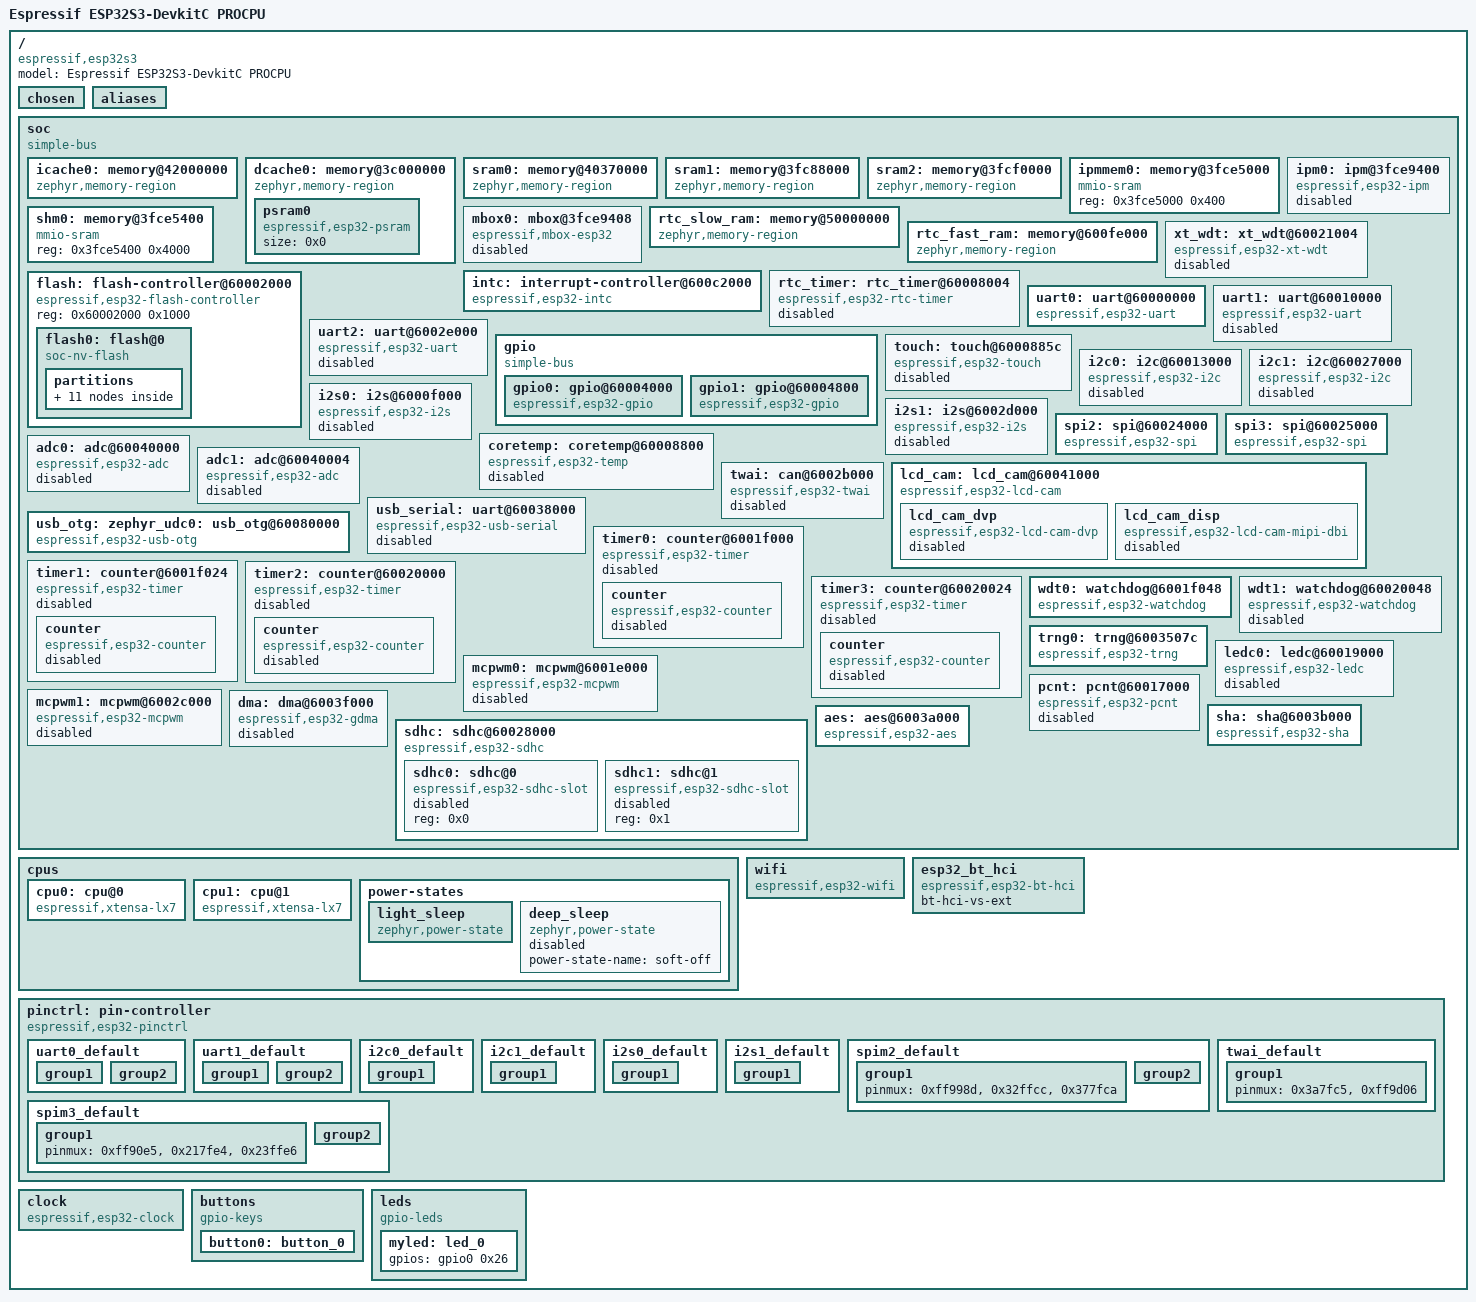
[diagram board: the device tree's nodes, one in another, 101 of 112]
/dts-v1/;

/* node '/' defined in zephyr\dts\common\skeleton.dtsi:9 */
/ {
	#address-cells = < 0x1 >;                   /* in zephyr\dts\common\skeleton.dtsi:10 */
	#size-cells = < 0x1 >;                      /* in zephyr\dts\common\skeleton.dtsi:11 */
	model = "Espressif ESP32S3-DevkitC PROCPU"; /* in zephyr\boards\espressif\esp32s3_devkitc\esp32s3_devkitc_procpu.dts:15 */
	compatible = "espressif,esp32s3";           /* in zephyr\boards\espressif\esp32s3_devkitc\esp32s3_devkitc_procpu.dts:16 */

	/* node '/chosen' defined in zephyr\dts\common\skeleton.dtsi:13 */
	chosen {
		zephyr,canbus = &twai;                    /* in zephyr\dts\xtensa\espressif\esp32s3\esp32s3_common.dtsi:22 */
		zephyr,entropy = &trng0;                  /* in zephyr\dts\xtensa\espressif\esp32s3\esp32s3_common.dtsi:23 */
		zephyr,flash-controller = &flash;         /* in zephyr\dts\xtensa\espressif\esp32s3\esp32s3_common.dtsi:24 */
		zephyr,sram = &sram1;                     /* in zephyr\boards\espressif\esp32s3_devkitc\esp32s3_devkitc_procpu.dts:26 */
		zephyr,console = &uart0;                  /* in zephyr\boards\espressif\esp32s3_devkitc\esp32s3_devkitc_procpu.dts:27 */
		zephyr,shell-uart = &uart0;               /* in zephyr\boards\espressif\esp32s3_devkitc\esp32s3_devkitc_procpu.dts:28 */
		zephyr,flash = &flash0;                   /* in zephyr\boards\espressif\esp32s3_devkitc\esp32s3_devkitc_procpu.dts:29 */
		zephyr,code-partition = &slot0_partition; /* in zephyr\boards\espressif\esp32s3_devkitc\esp32s3_devkitc_procpu.dts:30 */
		zephyr,bt-hci = &esp32_bt_hci;            /* in zephyr\boards\espressif\esp32s3_devkitc\esp32s3_devkitc_procpu.dts:31 */
	};

	/* node '/aliases' defined in zephyr\dts\common\skeleton.dtsi:15 */
	aliases {
		die-temp0 = &coretemp; /* in zephyr\dts\xtensa\espressif\esp32s3\esp32s3_common.dtsi:18 */
		i2c-0 = &i2c0;         /* in zephyr\boards\espressif\esp32s3_devkitc\esp32s3_devkitc_procpu.dts:19 */
		watchdog0 = &wdt0;     /* in zephyr\boards\espressif\esp32s3_devkitc\esp32s3_devkitc_procpu.dts:20 */
		uart-0 = &uart0;       /* in zephyr\boards\espressif\esp32s3_devkitc\esp32s3_devkitc_procpu.dts:21 */
		sw0 = &button0;        /* in zephyr\boards\espressif\esp32s3_devkitc\esp32s3_devkitc_procpu.dts:22 */
		led0 = &myled;         /* in ..\ZephyrWrokSpace\lomico\zephyr-course\my_work_space\hello_led\boards\esp32s3_devkitc_procpu.overlay:3 */
	};

	/* node '/soc' defined in zephyr\dts\xtensa\xtensa.dtsi:10 */
	soc {
		#address-cells = < 0x1 >;  /* in zephyr\dts\xtensa\espressif\esp32s3\esp32s3_common.dtsi:97 */
		#size-cells = < 0x1 >;     /* in zephyr\dts\xtensa\espressif\esp32s3\esp32s3_common.dtsi:98 */
		compatible = "simple-bus"; /* in zephyr\dts\xtensa\espressif\esp32s3\esp32s3_common.dtsi:99 */
		ranges;                    /* in zephyr\dts\xtensa\espressif\esp32s3\esp32s3_common.dtsi:100 */

		/* node '/soc/memory@42000000' defined in zephyr\dts\xtensa\espressif\esp32s3\esp32s3_common.dtsi:102 */
		icache0: memory@42000000 {
			compatible = "zephyr,memory-region"; /* in zephyr\dts\xtensa\espressif\esp32s3\esp32s3_common.dtsi:103 */
			reg = < 0x42000000 0x2000000 >;      /* in zephyr\dts\xtensa\espressif\esp32s3\esp32s3_common.dtsi:104 */
			zephyr,memory-region = "ICACHE0";    /* in zephyr\dts\xtensa\espressif\esp32s3\esp32s3_common.dtsi:105 */
		};

		/* node '/soc/memory@3c000000' defined in zephyr\dts\xtensa\espressif\esp32s3\esp32s3_common.dtsi:108 */
		dcache0: memory@3c000000 {
			compatible = "zephyr,memory-region"; /* in zephyr\dts\xtensa\espressif\esp32s3\esp32s3_common.dtsi:109 */
			reg = < 0x3c000000 0x2000000 >;      /* in zephyr\dts\xtensa\espressif\esp32s3\esp32s3_common.dtsi:110 */
			zephyr,memory-region = "DCACHE0";    /* in zephyr\dts\xtensa\espressif\esp32s3\esp32s3_common.dtsi:111 */

			/* node '/soc/memory@3c000000/psram0' defined in zephyr\dts\xtensa\espressif\esp32s3\esp32s3_common.dtsi:113 */
			psram0: psram0 {
				compatible = "espressif,esp32-psram"; /* in zephyr\dts\xtensa\espressif\esp32s3\esp32s3_common.dtsi:114 */
				size = < 0x0 >;                       /* in zephyr\dts\xtensa\espressif\esp32s3\esp32s3_common.dtsi:115 */
			};
		};

		/* node '/soc/memory@40370000' defined in zephyr\dts\xtensa\espressif\esp32s3\esp32s3_common.dtsi:119 */
		sram0: memory@40370000 {
			compatible = "zephyr,memory-region",
			             "mmio-sram";            /* in zephyr\dts\xtensa\espressif\esp32s3\esp32s3_common.dtsi:120 */
			reg = < 0x40370000 0x8000 >;         /* in zephyr\dts\xtensa\espressif\esp32s3\esp32s3_common.dtsi:121 */
			zephyr,memory-region = "SRAM0";      /* in zephyr\dts\xtensa\espressif\esp32s3\esp32s3_common.dtsi:122 */
		};

		/* node '/soc/memory@3fc88000' defined in zephyr\dts\xtensa\espressif\esp32s3\esp32s3_common.dtsi:125 */
		sram1: memory@3fc88000 {
			compatible = "zephyr,memory-region",
			             "mmio-sram";            /* in zephyr\dts\xtensa\espressif\esp32s3\esp32s3_common.dtsi:126 */
			reg = < 0x3fc88000 0x68000 >;        /* in zephyr\dts\xtensa\espressif\esp32s3\esp32s3_common.dtsi:127 */
			zephyr,memory-region = "SRAM1";      /* in zephyr\dts\xtensa\espressif\esp32s3\esp32s3_common.dtsi:128 */
		};

		/* node '/soc/memory@3fcf0000' defined in zephyr\dts\xtensa\espressif\esp32s3\esp32s3_common.dtsi:131 */
		sram2: memory@3fcf0000 {
			compatible = "zephyr,memory-region",
			             "mmio-sram";            /* in zephyr\dts\xtensa\espressif\esp32s3\esp32s3_common.dtsi:132 */
			reg = < 0x3fcf0000 0x10000 >;        /* in zephyr\dts\xtensa\espressif\esp32s3\esp32s3_common.dtsi:133 */
			zephyr,memory-region = "SRAM2";      /* in zephyr\dts\xtensa\espressif\esp32s3\esp32s3_common.dtsi:134 */
		};

		/* node '/soc/memory@3fce5000' defined in zephyr\dts\xtensa\espressif\esp32s3\esp32s3_common.dtsi:137 */
		ipmmem0: memory@3fce5000 {
			compatible = "mmio-sram";   /* in zephyr\dts\xtensa\espressif\esp32s3\esp32s3_common.dtsi:138 */
			reg = < 0x3fce5000 0x400 >; /* in zephyr\dts\xtensa\espressif\esp32s3\esp32s3_common.dtsi:139 */
			phandle = < 0x1 >;          /* in zephyr\dts\xtensa\espressif\esp32s3\esp32s3_common.dtsi:151 */
		};

		/* node '/soc/memory@3fce5400' defined in zephyr\dts\xtensa\espressif\esp32s3\esp32s3_common.dtsi:142 */
		shm0: memory@3fce5400 {
			compatible = "mmio-sram";    /* in zephyr\dts\xtensa\espressif\esp32s3\esp32s3_common.dtsi:143 */
			reg = < 0x3fce5400 0x4000 >; /* in zephyr\dts\xtensa\espressif\esp32s3\esp32s3_common.dtsi:144 */
		};

		/* node '/soc/ipm@3fce9400' defined in zephyr\dts\xtensa\espressif\esp32s3\esp32s3_common.dtsi:147 */
		ipm0: ipm@3fce9400 {
			compatible = "espressif,esp32-ipm"; /* in zephyr\dts\xtensa\espressif\esp32s3\esp32s3_common.dtsi:148 */
			reg = < 0x3fce9400 0x8 >;           /* in zephyr\dts\xtensa\espressif\esp32s3\esp32s3_common.dtsi:149 */
			status = "disabled";                /* in zephyr\dts\xtensa\espressif\esp32s3\esp32s3_common.dtsi:150 */
			shared-memory = < &ipmmem0 >;       /* in zephyr\dts\xtensa\espressif\esp32s3\esp32s3_common.dtsi:151 */
			shared-memory-size = < 0x400 >;     /* in zephyr\dts\xtensa\espressif\esp32s3\esp32s3_common.dtsi:152 */
			interrupts = < 0x4f 0x0 0x0 >,
			             < 0x50 0x0 0x0 >;      /* in zephyr\dts\xtensa\espressif\esp32s3\esp32s3_common.dtsi:153 */
			interrupt-parent = < &intc >;       /* in zephyr\dts\xtensa\espressif\esp32s3\esp32s3_common.dtsi:155 */
		};

		/* node '/soc/mbox@3fce9408' defined in zephyr\dts\xtensa\espressif\esp32s3\esp32s3_common.dtsi:158 */
		mbox0: mbox@3fce9408 {
			compatible = "espressif,mbox-esp32"; /* in zephyr\dts\xtensa\espressif\esp32s3\esp32s3_common.dtsi:159 */
			reg = < 0x3fce9408 0x8 >;            /* in zephyr\dts\xtensa\espressif\esp32s3\esp32s3_common.dtsi:160 */
			status = "disabled";                 /* in zephyr\dts\xtensa\espressif\esp32s3\esp32s3_common.dtsi:161 */
			shared-memory = < &ipmmem0 >;        /* in zephyr\dts\xtensa\espressif\esp32s3\esp32s3_common.dtsi:162 */
			shared-memory-size = < 0x400 >;      /* in zephyr\dts\xtensa\espressif\esp32s3\esp32s3_common.dtsi:163 */
			interrupts = < 0x4f 0x0 0x0 >,
			             < 0x50 0x0 0x0 >;       /* in zephyr\dts\xtensa\espressif\esp32s3\esp32s3_common.dtsi:164 */
			interrupt-parent = < &intc >;        /* in zephyr\dts\xtensa\espressif\esp32s3\esp32s3_common.dtsi:166 */
			#mbox-cells = < 0x1 >;               /* in zephyr\dts\xtensa\espressif\esp32s3\esp32s3_common.dtsi:167 */
		};

		/* node '/soc/memory@50000000' defined in zephyr\dts\xtensa\espressif\esp32s3\esp32s3_common.dtsi:170 */
		rtc_slow_ram: memory@50000000 {
			compatible = "zephyr,memory-region",
			             "mmio-sram";              /* in zephyr\dts\xtensa\espressif\esp32s3\esp32s3_common.dtsi:171 */
			reg = < 0x50000000 0x2000 >;           /* in zephyr\dts\xtensa\espressif\esp32s3\esp32s3_common.dtsi:172 */
			zephyr,memory-region = "RTC_SLOW_RAM"; /* in zephyr\dts\xtensa\espressif\esp32s3\esp32s3_common.dtsi:173 */
		};

		/* node '/soc/memory@600fe000' defined in zephyr\dts\xtensa\espressif\esp32s3\esp32s3_common.dtsi:176 */
		rtc_fast_ram: memory@600fe000 {
			compatible = "zephyr,memory-region",
			             "mmio-sram";              /* in zephyr\dts\xtensa\espressif\esp32s3\esp32s3_common.dtsi:177 */
			reg = < 0x600fe000 0x2000 >;           /* in zephyr\dts\xtensa\espressif\esp32s3\esp32s3_common.dtsi:178 */
			zephyr,memory-region = "RTC_FAST_RAM"; /* in zephyr\dts\xtensa\espressif\esp32s3\esp32s3_common.dtsi:179 */
		};

		/* node '/soc/interrupt-controller@600c2000' defined in zephyr\dts\xtensa\espressif\esp32s3\esp32s3_common.dtsi:182 */
		intc: interrupt-controller@600c2000 {
			#interrupt-cells = < 0x3 >;          /* in zephyr\dts\xtensa\espressif\esp32s3\esp32s3_common.dtsi:183 */
			#address-cells = < 0x0 >;            /* in zephyr\dts\xtensa\espressif\esp32s3\esp32s3_common.dtsi:184 */
			compatible = "espressif,esp32-intc"; /* in zephyr\dts\xtensa\espressif\esp32s3\esp32s3_common.dtsi:185 */
			interrupt-controller;                /* in zephyr\dts\xtensa\espressif\esp32s3\esp32s3_common.dtsi:186 */
			reg = < 0x600c2000 0x1000 >;         /* in zephyr\dts\xtensa\espressif\esp32s3\esp32s3_common.dtsi:187 */
			status = "okay";                     /* in zephyr\dts\xtensa\espressif\esp32s3\esp32s3_common.dtsi:188 */
			phandle = < 0x2 >;                   /* in zephyr\dts\xtensa\espressif\esp32s3\esp32s3_common.dtsi:155 */
		};

		/* node '/soc/xt_wdt@60021004' defined in zephyr\dts\xtensa\espressif\esp32s3\esp32s3_common.dtsi:191 */
		xt_wdt: xt_wdt@60021004 {
			compatible = "espressif,esp32-xt-wdt"; /* in zephyr\dts\xtensa\espressif\esp32s3\esp32s3_common.dtsi:192 */
			reg = < 0x60021004 0x4 >;              /* in zephyr\dts\xtensa\espressif\esp32s3\esp32s3_common.dtsi:193 */
			clocks = < &clock 0xc >;               /* in zephyr\dts\xtensa\espressif\esp32s3\esp32s3_common.dtsi:194 */
			interrupts = < 0x27 0x0 0x0 >;         /* in zephyr\dts\xtensa\espressif\esp32s3\esp32s3_common.dtsi:195 */
			interrupt-parent = < &intc >;          /* in zephyr\dts\xtensa\espressif\esp32s3\esp32s3_common.dtsi:196 */
			status = "disabled";                   /* in zephyr\dts\xtensa\espressif\esp32s3\esp32s3_common.dtsi:197 */
		};

		/* node '/soc/rtc_timer@60008004' defined in zephyr\dts\xtensa\espressif\esp32s3\esp32s3_common.dtsi:200 */
		rtc_timer: rtc_timer@60008004 {
			reg = < 0x60008004 0xc >;                 /* in zephyr\dts\xtensa\espressif\esp32s3\esp32s3_common.dtsi:201 */
			compatible = "espressif,esp32-rtc-timer"; /* in zephyr\dts\xtensa\espressif\esp32s3\esp32s3_common.dtsi:202 */
			clocks = < &clock 0xc >;                  /* in zephyr\dts\xtensa\espressif\esp32s3\esp32s3_common.dtsi:203 */
			interrupts = < 0x27 0x0 0x0 >;            /* in zephyr\dts\xtensa\espressif\esp32s3\esp32s3_common.dtsi:204 */
			interrupt-parent = < &intc >;             /* in zephyr\dts\xtensa\espressif\esp32s3\esp32s3_common.dtsi:205 */
			status = "disabled";                      /* in zephyr\dts\xtensa\espressif\esp32s3\esp32s3_common.dtsi:206 */
		};

		/* node '/soc/flash-controller@60002000' defined in zephyr\dts\xtensa\espressif\esp32s3\esp32s3_common.dtsi:209 */
		flash: flash-controller@60002000 {
			compatible = "espressif,esp32-flash-controller"; /* in zephyr\dts\xtensa\espressif\esp32s3\esp32s3_common.dtsi:210 */
			reg = < 0x60002000 0x1000 >;                     /* in zephyr\dts\xtensa\espressif\esp32s3\esp32s3_common.dtsi:211 */
			#address-cells = < 0x1 >;                        /* in zephyr\dts\xtensa\espressif\esp32s3\esp32s3_common.dtsi:212 */
			#size-cells = < 0x1 >;                           /* in zephyr\dts\xtensa\espressif\esp32s3\esp32s3_common.dtsi:213 */
			ranges;                                          /* in zephyr\dts\xtensa\espressif\esp32s3\esp32s3_common.dtsi:214 */

			/* node '/soc/flash-controller@60002000/flash@0' defined in zephyr\dts\xtensa\espressif\esp32s3\esp32s3_common.dtsi:216 */
			flash0: flash@0 {
				compatible = "soc-nv-flash";   /* in zephyr\dts\xtensa\espressif\esp32s3\esp32s3_common.dtsi:217 */
				erase-block-size = < 0x1000 >; /* in zephyr\dts\xtensa\espressif\esp32s3\esp32s3_common.dtsi:218 */
				write-block-size = < 0x4 >;    /* in zephyr\dts\xtensa\espressif\esp32s3\esp32s3_common.dtsi:219 */
				#address-cells = < 0x1 >;      /* in zephyr\dts\xtensa\espressif\esp32s3\esp32s3_common.dtsi:220 */
				#size-cells = < 0x1 >;         /* in zephyr\dts\xtensa\espressif\esp32s3\esp32s3_common.dtsi:221 */
				reg = < 0x0 0x800000 >;        /* in zephyr\dts\xtensa\espressif\esp32s3\esp32s3_wroom_n8.dtsi:11 */
				ranges = < 0x0 0x0 0x800000 >; /* in zephyr\dts\xtensa\espressif\esp32s3\esp32s3_wroom_n8.dtsi:12 */

				/* node '/soc/flash-controller@60002000/flash@0/partitions' defined in zephyr\dts\vendor\espressif\partitions_0x0_amp_4M.dtsi:8 */
				partitions {
					ranges;                   /* in zephyr\dts\vendor\espressif\partitions_0x0_amp_4M.dtsi:9 */
					#address-cells = < 0x1 >; /* in zephyr\dts\vendor\espressif\partitions_0x0_amp_4M.dtsi:10 */
					#size-cells = < 0x1 >;    /* in zephyr\dts\vendor\espressif\partitions_0x0_amp_4M.dtsi:11 */

					/* node '/soc/flash-controller@60002000/flash@0/partitions/partition@0' defined in zephyr\dts\vendor\espressif\partitions_0x0_amp_4M.dtsi:13 */
					boot_partition: partition@0 {
						compatible = "zephyr,mapped-partition"; /* in zephyr\dts\vendor\espressif\partitions_0x0_amp_4M.dtsi:14 */
						label = "mcuboot";                      /* in zephyr\dts\vendor\espressif\partitions_0x0_amp_4M.dtsi:15 */
						reg = < 0x0 0x10000 >;                  /* in zephyr\dts\vendor\espressif\partitions_0x0_amp_4M.dtsi:16 */
					};

					/* node '/soc/flash-controller@60002000/flash@0/partitions/partition@10000' defined in zephyr\dts\vendor\espressif\partitions_0x0_amp_4M.dtsi:19 */
					sys_partition: partition@10000 {
						compatible = "zephyr,mapped-partition"; /* in zephyr\dts\vendor\espressif\partitions_0x0_amp_4M.dtsi:20 */
						label = "sys";                          /* in zephyr\dts\vendor\espressif\partitions_0x0_amp_4M.dtsi:21 */
						reg = < 0x10000 0x10000 >;              /* in zephyr\dts\vendor\espressif\partitions_0x0_amp_4M.dtsi:22 */
					};

					/* node '/soc/flash-controller@60002000/flash@0/partitions/partition@20000' defined in zephyr\dts\vendor\espressif\partitions_0x0_amp_4M.dtsi:25 */
					slot0_partition: partition@20000 {
						compatible = "zephyr,mapped-partition"; /* in zephyr\dts\vendor\espressif\partitions_0x0_amp_4M.dtsi:26 */
						label = "image-0";                      /* in zephyr\dts\vendor\espressif\partitions_0x0_amp_4M.dtsi:27 */
						reg = < 0x20000 0x150000 >;             /* in zephyr\dts\vendor\espressif\partitions_0x0_amp_4M.dtsi:28 */
					};

					/* node '/soc/flash-controller@60002000/flash@0/partitions/partition@170000' defined in zephyr\dts\vendor\espressif\partitions_0x0_amp_4M.dtsi:31 */
					slot1_partition: partition@170000 {
						compatible = "zephyr,mapped-partition"; /* in zephyr\dts\vendor\espressif\partitions_0x0_amp_4M.dtsi:32 */
						label = "image-1";                      /* in zephyr\dts\vendor\espressif\partitions_0x0_amp_4M.dtsi:33 */
						reg = < 0x170000 0x150000 >;            /* in zephyr\dts\vendor\espressif\partitions_0x0_amp_4M.dtsi:34 */
					};

					/* node '/soc/flash-controller@60002000/flash@0/partitions/partition@2c0000' defined in zephyr\dts\vendor\espressif\partitions_0x0_amp_4M.dtsi:37 */
					slot0_appcpu_partition: partition@2c0000 {
						compatible = "zephyr,mapped-partition"; /* in zephyr\dts\vendor\espressif\partitions_0x0_amp_4M.dtsi:38 */
						label = "image-0-appcpu";               /* in zephyr\dts\vendor\espressif\partitions_0x0_amp_4M.dtsi:39 */
						reg = < 0x2c0000 0x70000 >;             /* in zephyr\dts\vendor\espressif\partitions_0x0_amp_4M.dtsi:40 */
					};

					/* node '/soc/flash-controller@60002000/flash@0/partitions/partition@330000' defined in zephyr\dts\vendor\espressif\partitions_0x0_amp_4M.dtsi:43 */
					slot1_appcpu_partition: partition@330000 {
						compatible = "zephyr,mapped-partition"; /* in zephyr\dts\vendor\espressif\partitions_0x0_amp_4M.dtsi:44 */
						label = "image-1-appcpu";               /* in zephyr\dts\vendor\espressif\partitions_0x0_amp_4M.dtsi:45 */
						reg = < 0x330000 0x70000 >;             /* in zephyr\dts\vendor\espressif\partitions_0x0_amp_4M.dtsi:46 */
					};

					/* node '/soc/flash-controller@60002000/flash@0/partitions/partition@3a0000' defined in zephyr\dts\vendor\espressif\partitions_0x0_amp_4M.dtsi:49 */
					slot0_lpcore_partition: partition@3a0000 {
						compatible = "zephyr,mapped-partition"; /* in zephyr\dts\vendor\espressif\partitions_0x0_amp_4M.dtsi:50 */
						label = "image-0-lpcore";               /* in zephyr\dts\vendor\espressif\partitions_0x0_amp_4M.dtsi:51 */
						reg = < 0x3a0000 0x8000 >;              /* in zephyr\dts\vendor\espressif\partitions_0x0_amp_4M.dtsi:52 */
					};

					/* node '/soc/flash-controller@60002000/flash@0/partitions/partition@3a8000' defined in zephyr\dts\vendor\espressif\partitions_0x0_amp_4M.dtsi:55 */
					slot1_lpcore_partition: partition@3a8000 {
						compatible = "zephyr,mapped-partition"; /* in zephyr\dts\vendor\espressif\partitions_0x0_amp_4M.dtsi:56 */
						label = "image-1-lpcore";               /* in zephyr\dts\vendor\espressif\partitions_0x0_amp_4M.dtsi:57 */
						reg = < 0x3a8000 0x8000 >;              /* in zephyr\dts\vendor\espressif\partitions_0x0_amp_4M.dtsi:58 */
					};

					/* node '/soc/flash-controller@60002000/flash@0/partitions/partition@3b0000' defined in zephyr\dts\vendor\espressif\partitions_0x0_amp_4M.dtsi:61 */
					storage_partition: partition@3b0000 {
						compatible = "zephyr,mapped-partition"; /* in zephyr\dts\vendor\espressif\partitions_0x0_amp_4M.dtsi:62 */
						label = "storage";                      /* in zephyr\dts\vendor\espressif\partitions_0x0_amp_4M.dtsi:63 */
						reg = < 0x3b0000 0x30000 >;             /* in zephyr\dts\vendor\espressif\partitions_0x0_amp_4M.dtsi:64 */
					};

					/* node '/soc/flash-controller@60002000/flash@0/partitions/partition@3e0000' defined in zephyr\dts\vendor\espressif\partitions_0x0_amp_4M.dtsi:67 */
					scratch_partition: partition@3e0000 {
						compatible = "zephyr,mapped-partition"; /* in zephyr\dts\vendor\espressif\partitions_0x0_amp_4M.dtsi:68 */
						label = "image-scratch";                /* in zephyr\dts\vendor\espressif\partitions_0x0_amp_4M.dtsi:69 */
						reg = < 0x3e0000 0x1f000 >;             /* in zephyr\dts\vendor\espressif\partitions_0x0_amp_4M.dtsi:70 */
					};

					/* node '/soc/flash-controller@60002000/flash@0/partitions/partition@3ff000' defined in zephyr\dts\vendor\espressif\partitions_0x0_amp_4M.dtsi:73 */
					coredump_partition: partition@3ff000 {
						compatible = "zephyr,mapped-partition"; /* in zephyr\dts\vendor\espressif\partitions_0x0_amp_4M.dtsi:74 */
						label = "coredump";                     /* in zephyr\dts\vendor\espressif\partitions_0x0_amp_4M.dtsi:75 */
						reg = < 0x3ff000 0x1000 >;              /* in zephyr\dts\vendor\espressif\partitions_0x0_amp_4M.dtsi:76 */
					};
				};
			};
		};

		/* node '/soc/uart@60000000' defined in zephyr\dts\xtensa\espressif\esp32s3\esp32s3_common.dtsi:226 */
		uart0: uart@60000000 {
			compatible = "espressif,esp32-uart"; /* in zephyr\dts\xtensa\espressif\esp32s3\esp32s3_common.dtsi:227 */
			reg = < 0x60000000 0x1000 >;         /* in zephyr\dts\xtensa\espressif\esp32s3\esp32s3_common.dtsi:228 */
			interrupts = < 0x1b 0x0 0x0 >;       /* in zephyr\dts\xtensa\espressif\esp32s3\esp32s3_common.dtsi:229 */
			interrupt-parent = < &intc >;        /* in zephyr\dts\xtensa\espressif\esp32s3\esp32s3_common.dtsi:230 */
			clocks = < &clock 0x65 >;            /* in zephyr\dts\xtensa\espressif\esp32s3\esp32s3_common.dtsi:231 */
			status = "okay";                     /* in zephyr\boards\espressif\esp32s3_devkitc\esp32s3_devkitc_procpu.dts:50 */
			current-speed = < 0x1c200 >;         /* in zephyr\boards\espressif\esp32s3_devkitc\esp32s3_devkitc_procpu.dts:51 */
			pinctrl-0 = < &uart0_default >;      /* in zephyr\boards\espressif\esp32s3_devkitc\esp32s3_devkitc_procpu.dts:52 */
			pinctrl-names = "default";           /* in zephyr\boards\espressif\esp32s3_devkitc\esp32s3_devkitc_procpu.dts:53 */
		};

		/* node '/soc/uart@60010000' defined in zephyr\dts\xtensa\espressif\esp32s3\esp32s3_common.dtsi:235 */
		uart1: uart@60010000 {
			compatible = "espressif,esp32-uart"; /* in zephyr\dts\xtensa\espressif\esp32s3\esp32s3_common.dtsi:236 */
			reg = < 0x60010000 0x1000 >;         /* in zephyr\dts\xtensa\espressif\esp32s3\esp32s3_common.dtsi:237 */
			interrupts = < 0x1c 0x0 0x0 >;       /* in zephyr\dts\xtensa\espressif\esp32s3\esp32s3_common.dtsi:238 */
			interrupt-parent = < &intc >;        /* in zephyr\dts\xtensa\espressif\esp32s3\esp32s3_common.dtsi:239 */
			clocks = < &clock 0x0 >;             /* in zephyr\dts\xtensa\espressif\esp32s3\esp32s3_common.dtsi:240 */
			status = "disabled";                 /* in zephyr\dts\xtensa\espressif\esp32s3\esp32s3_common.dtsi:241 */
		};

		/* node '/soc/uart@6002e000' defined in zephyr\dts\xtensa\espressif\esp32s3\esp32s3_common.dtsi:244 */
		uart2: uart@6002e000 {
			compatible = "espressif,esp32-uart"; /* in zephyr\dts\xtensa\espressif\esp32s3\esp32s3_common.dtsi:245 */
			reg = < 0x6002e000 0x1000 >;         /* in zephyr\dts\xtensa\espressif\esp32s3\esp32s3_common.dtsi:246 */
			interrupts = < 0x1d 0x0 0x0 >;       /* in zephyr\dts\xtensa\espressif\esp32s3\esp32s3_common.dtsi:247 */
			interrupt-parent = < &intc >;        /* in zephyr\dts\xtensa\espressif\esp32s3\esp32s3_common.dtsi:248 */
			clocks = < &clock 0x1 >;             /* in zephyr\dts\xtensa\espressif\esp32s3\esp32s3_common.dtsi:249 */
			status = "disabled";                 /* in zephyr\dts\xtensa\espressif\esp32s3\esp32s3_common.dtsi:250 */
		};

		/* node '/soc/gpio' defined in zephyr\dts\xtensa\espressif\esp32s3\esp32s3_common.dtsi:253 */
		gpio: gpio {
			compatible = "simple-bus";                                     /* in zephyr\dts\xtensa\espressif\esp32s3\esp32s3_common.dtsi:254 */
			gpio-map-mask = < 0xffffffe0 0xffffffc0 >;                     /* in zephyr\dts\xtensa\espressif\esp32s3\esp32s3_common.dtsi:255 */
			gpio-map-pass-thru = < 0x1f 0x3f >;                            /* in zephyr\dts\xtensa\espressif\esp32s3\esp32s3_common.dtsi:256 */
			gpio-map = < 0x0 0x0 &gpio0 0x0 0x0 0x20 0x0 &gpio1 0x0 0x0 >; /* in zephyr\dts\xtensa\espressif\esp32s3\esp32s3_common.dtsi:257 */
			#gpio-cells = < 0x2 >;                                         /* in zephyr\dts\xtensa\espressif\esp32s3\esp32s3_common.dtsi:259 */
			#address-cells = < 0x1 >;                                      /* in zephyr\dts\xtensa\espressif\esp32s3\esp32s3_common.dtsi:260 */
			#size-cells = < 0x1 >;                                         /* in zephyr\dts\xtensa\espressif\esp32s3\esp32s3_common.dtsi:261 */
			ranges;                                                        /* in zephyr\dts\xtensa\espressif\esp32s3\esp32s3_common.dtsi:262 */

			/* node '/soc/gpio/gpio@60004000' defined in zephyr\dts\xtensa\espressif\esp32s3\esp32s3_common.dtsi:264 */
			gpio0: gpio@60004000 {
				compatible = "espressif,esp32-gpio"; /* in zephyr\dts\xtensa\espressif\esp32s3\esp32s3_common.dtsi:265 */
				gpio-controller;                     /* in zephyr\dts\xtensa\espressif\esp32s3\esp32s3_common.dtsi:266 */
				#gpio-cells = < 0x2 >;               /* in zephyr\dts\xtensa\espressif\esp32s3\esp32s3_common.dtsi:267 */
				reg = < 0x60004000 0x800 >;          /* in zephyr\dts\xtensa\espressif\esp32s3\esp32s3_common.dtsi:268 */
				interrupts = < 0x10 0x0 0x0 >;       /* in zephyr\dts\xtensa\espressif\esp32s3\esp32s3_common.dtsi:269 */
				interrupt-parent = < &intc >;        /* in zephyr\dts\xtensa\espressif\esp32s3\esp32s3_common.dtsi:270 */
				ngpios = < 0x20 >;                   /* in zephyr\dts\xtensa\espressif\esp32s3\esp32s3_common.dtsi:276 */
				status = "okay";                     /* in ..\ZephyrWrokSpace\lomico\zephyr-course\my_work_space\hello_led\boards\esp32s3_devkitc_procpu.overlay:8 */
				phandle = < 0x5 >;                   /* in zephyr\dts\xtensa\espressif\esp32s3\esp32s3_common.dtsi:257 */
			};

			/* node '/soc/gpio/gpio@60004800' defined in zephyr\dts\xtensa\espressif\esp32s3\esp32s3_common.dtsi:279 */
			gpio1: gpio@60004800 {
				compatible = "espressif,esp32-gpio"; /* in zephyr\dts\xtensa\espressif\esp32s3\esp32s3_common.dtsi:280 */
				gpio-controller;                     /* in zephyr\dts\xtensa\espressif\esp32s3\esp32s3_common.dtsi:281 */
				#gpio-cells = < 0x2 >;               /* in zephyr\dts\xtensa\espressif\esp32s3\esp32s3_common.dtsi:282 */
				reg = < 0x60004800 0x800 >;          /* in zephyr\dts\xtensa\espressif\esp32s3\esp32s3_common.dtsi:283 */
				interrupts = < 0x10 0x0 0x0 >;       /* in zephyr\dts\xtensa\espressif\esp32s3\esp32s3_common.dtsi:284 */
				interrupt-parent = < &intc >;        /* in zephyr\dts\xtensa\espressif\esp32s3\esp32s3_common.dtsi:285 */
				ngpios = < 0x16 >;                   /* in zephyr\dts\xtensa\espressif\esp32s3\esp32s3_common.dtsi:286 */
				status = "okay";                     /* in zephyr\boards\espressif\esp32s3_devkitc\esp32s3_devkitc_procpu.dts:61 */
				phandle = < 0x6 >;                   /* in zephyr\dts\xtensa\espressif\esp32s3\esp32s3_common.dtsi:257 */
			};
		};

		/* node '/soc/touch@6000885c' defined in zephyr\dts\xtensa\espressif\esp32s3\esp32s3_common.dtsi:290 */
		touch: touch@6000885c {
			compatible = "espressif,esp32-touch";      /* in zephyr\dts\xtensa\espressif\esp32s3\esp32s3_common.dtsi:291 */
			reg = < 0x6000885c 0x88 0x60008908 0x18 >; /* in zephyr\dts\xtensa\espressif\esp32s3\esp32s3_common.dtsi:292 */
			interrupts = < 0x27 0x0 0x0 >;             /* in zephyr\dts\xtensa\espressif\esp32s3\esp32s3_common.dtsi:293 */
			interrupt-parent = < &intc >;              /* in zephyr\dts\xtensa\espressif\esp32s3\esp32s3_common.dtsi:294 */
			status = "disabled";                       /* in zephyr\dts\xtensa\espressif\esp32s3\esp32s3_common.dtsi:295 */
			debounce-interval-ms = < 0x1e >;           /* in zephyr\boards\espressif\esp32s3_devkitc\esp32s3_devkitc_procpu.dts:65 */
			href-microvolt = < 0x2932e0 >;             /* in zephyr\boards\espressif\esp32s3_devkitc\esp32s3_devkitc_procpu.dts:66 */
			lref-microvolt = < 0x7a120 >;              /* in zephyr\boards\espressif\esp32s3_devkitc\esp32s3_devkitc_procpu.dts:67 */
			href-atten-microvolt = < 0xf4240 >;        /* in zephyr\boards\espressif\esp32s3_devkitc\esp32s3_devkitc_procpu.dts:68 */
			filter-mode = < 0x2 >;                     /* in zephyr\boards\espressif\esp32s3_devkitc\esp32s3_devkitc_procpu.dts:69 */
			filter-debounce-cnt = < 0x1 >;             /* in zephyr\boards\espressif\esp32s3_devkitc\esp32s3_devkitc_procpu.dts:70 */
			filter-noise-thr = < 0x0 >;                /* in zephyr\boards\espressif\esp32s3_devkitc\esp32s3_devkitc_procpu.dts:71 */
			filter-jitter-step = < 0x4 >;              /* in zephyr\boards\espressif\esp32s3_devkitc\esp32s3_devkitc_procpu.dts:72 */
			filter-smooth-level = < 0x1 >;             /* in zephyr\boards\espressif\esp32s3_devkitc\esp32s3_devkitc_procpu.dts:73 */
		};

		/* node '/soc/i2c@60013000' defined in zephyr\dts\xtensa\espressif\esp32s3\esp32s3_common.dtsi:298 */
		i2c0: i2c@60013000 {
			compatible = "espressif,esp32-i2c"; /* in zephyr\dts\xtensa\espressif\esp32s3\esp32s3_common.dtsi:299 */
			#address-cells = < 0x1 >;           /* in zephyr\dts\xtensa\espressif\esp32s3\esp32s3_common.dtsi:300 */
			#size-cells = < 0x0 >;              /* in zephyr\dts\xtensa\espressif\esp32s3\esp32s3_common.dtsi:301 */
			reg = < 0x60013000 0x1000 >;        /* in zephyr\dts\xtensa\espressif\esp32s3\esp32s3_common.dtsi:302 */
			interrupts = < 0x2a 0x0 0x0 >;      /* in zephyr\dts\xtensa\espressif\esp32s3\esp32s3_common.dtsi:303 */
			interrupt-parent = < &intc >;       /* in zephyr\dts\xtensa\espressif\esp32s3\esp32s3_common.dtsi:304 */
			clocks = < &clock 0x67 >;           /* in zephyr\dts\xtensa\espressif\esp32s3\esp32s3_common.dtsi:305 */
			status = "disabled";                /* in zephyr\dts\xtensa\espressif\esp32s3\esp32s3_common.dtsi:306 */
			clock-frequency = < 0x186a0 >;      /* in zephyr\boards\espressif\esp32s3_devkitc\esp32s3_devkitc_procpu.dts:77 */
			pinctrl-0 = < &i2c0_default >;      /* in zephyr\boards\espressif\esp32s3_devkitc\esp32s3_devkitc_procpu.dts:78 */
			pinctrl-names = "default";          /* in zephyr\boards\espressif\esp32s3_devkitc\esp32s3_devkitc_procpu.dts:79 */
		};

		/* node '/soc/i2c@60027000' defined in zephyr\dts\xtensa\espressif\esp32s3\esp32s3_common.dtsi:309 */
		i2c1: i2c@60027000 {
			compatible = "espressif,esp32-i2c"; /* in zephyr\dts\xtensa\espressif\esp32s3\esp32s3_common.dtsi:310 */
			#address-cells = < 0x1 >;           /* in zephyr\dts\xtensa\espressif\esp32s3\esp32s3_common.dtsi:311 */
			#size-cells = < 0x0 >;              /* in zephyr\dts\xtensa\espressif\esp32s3\esp32s3_common.dtsi:312 */
			reg = < 0x60027000 0x1000 >;        /* in zephyr\dts\xtensa\espressif\esp32s3\esp32s3_common.dtsi:313 */
			interrupts = < 0x2b 0x0 0x0 >;      /* in zephyr\dts\xtensa\espressif\esp32s3\esp32s3_common.dtsi:314 */
			interrupt-parent = < &intc >;       /* in zephyr\dts\xtensa\espressif\esp32s3\esp32s3_common.dtsi:315 */
			clocks = < &clock 0x68 >;           /* in zephyr\dts\xtensa\espressif\esp32s3\esp32s3_common.dtsi:316 */
			status = "disabled";                /* in zephyr\dts\xtensa\espressif\esp32s3\esp32s3_common.dtsi:317 */
			clock-frequency = < 0x186a0 >;      /* in zephyr\boards\espressif\esp32s3_devkitc\esp32s3_devkitc_procpu.dts:83 */
			pinctrl-0 = < &i2c1_default >;      /* in zephyr\boards\espressif\esp32s3_devkitc\esp32s3_devkitc_procpu.dts:84 */
			pinctrl-names = "default";          /* in zephyr\boards\espressif\esp32s3_devkitc\esp32s3_devkitc_procpu.dts:85 */
		};

		/* node '/soc/i2s@6000f000' defined in zephyr\dts\xtensa\espressif\esp32s3\esp32s3_common.dtsi:320 */
		i2s0: i2s@6000f000 {
			compatible = "espressif,esp32-i2s"; /* in zephyr\dts\xtensa\espressif\esp32s3\esp32s3_common.dtsi:321 */
			#address-cells = < 0x1 >;           /* in zephyr\dts\xtensa\espressif\esp32s3\esp32s3_common.dtsi:322 */
			#size-cells = < 0x0 >;              /* in zephyr\dts\xtensa\espressif\esp32s3\esp32s3_common.dtsi:323 */
			reg = < 0x6000f000 0x1000 >;        /* in zephyr\dts\xtensa\espressif\esp32s3\esp32s3_common.dtsi:324 */
			interrupts = < 0x19 0x0 0x0 >;      /* in zephyr\dts\xtensa\espressif\esp32s3\esp32s3_common.dtsi:325 */
			interrupt-parent = < &intc >;       /* in zephyr\dts\xtensa\espressif\esp32s3\esp32s3_common.dtsi:326 */
			clocks = < &clock 0x69 >;           /* in zephyr\dts\xtensa\espressif\esp32s3\esp32s3_common.dtsi:327 */
			dmas = < &dma 0x2 >,
			       < &dma 0x3 >;                /* in zephyr\dts\xtensa\espressif\esp32s3\esp32s3_common.dtsi:328 */
			dma-names = "rx",
			            "tx";                   /* in zephyr\dts\xtensa\espressif\esp32s3\esp32s3_common.dtsi:329 */
			unit = < 0x0 >;                     /* in zephyr\dts\xtensa\espressif\esp32s3\esp32s3_common.dtsi:330 */
			status = "disabled";                /* in zephyr\dts\xtensa\espressif\esp32s3\esp32s3_common.dtsi:331 */
			pinctrl-0 = < &i2s0_default >;      /* in zephyr\boards\espressif\esp32s3_devkitc\esp32s3_devkitc_procpu.dts:89 */
			pinctrl-names = "default";          /* in zephyr\boards\espressif\esp32s3_devkitc\esp32s3_devkitc_procpu.dts:90 */
		};

		/* node '/soc/i2s@6002d000' defined in zephyr\dts\xtensa\espressif\esp32s3\esp32s3_common.dtsi:334 */
		i2s1: i2s@6002d000 {
			compatible = "espressif,esp32-i2s"; /* in zephyr\dts\xtensa\espressif\esp32s3\esp32s3_common.dtsi:335 */
			#address-cells = < 0x1 >;           /* in zephyr\dts\xtensa\espressif\esp32s3\esp32s3_common.dtsi:336 */
			#size-cells = < 0x0 >;              /* in zephyr\dts\xtensa\espressif\esp32s3\esp32s3_common.dtsi:337 */
			reg = < 0x6002d000 0x1000 >;        /* in zephyr\dts\xtensa\espressif\esp32s3\esp32s3_common.dtsi:338 */
			interrupts = < 0x1a 0x0 0x0 >;      /* in zephyr\dts\xtensa\espressif\esp32s3\esp32s3_common.dtsi:339 */
			interrupt-parent = < &intc >;       /* in zephyr\dts\xtensa\espressif\esp32s3\esp32s3_common.dtsi:340 */
			clocks = < &clock 0x6a >;           /* in zephyr\dts\xtensa\espressif\esp32s3\esp32s3_common.dtsi:341 */
			dmas = < &dma 0x4 >,
			       < &dma 0x5 >;                /* in zephyr\dts\xtensa\espressif\esp32s3\esp32s3_common.dtsi:342 */
			dma-names = "rx",
			            "tx";                   /* in zephyr\dts\xtensa\espressif\esp32s3\esp32s3_common.dtsi:343 */
			unit = < 0x1 >;                     /* in zephyr\dts\xtensa\espressif\esp32s3\esp32s3_common.dtsi:344 */
			status = "disabled";                /* in zephyr\dts\xtensa\espressif\esp32s3\esp32s3_common.dtsi:345 */
			pinctrl-0 = < &i2s1_default >;      /* in zephyr\boards\espressif\esp32s3_devkitc\esp32s3_devkitc_procpu.dts:94 */
			pinctrl-names = "default";          /* in zephyr\boards\espressif\esp32s3_devkitc\esp32s3_devkitc_procpu.dts:95 */
		};

		/* node '/soc/spi@60024000' defined in zephyr\dts\xtensa\espressif\esp32s3\esp32s3_common.dtsi:348 */
		spi2: spi@60024000 {
			compatible = "espressif,esp32-spi"; /* in zephyr\dts\xtensa\espressif\esp32s3\esp32s3_common.dtsi:349 */
			reg = < 0x60024000 0x1000 >;        /* in zephyr\dts\xtensa\espressif\esp32s3\esp32s3_common.dtsi:350 */
			interrupts = < 0x15 0x0 0x0 >;      /* in zephyr\dts\xtensa\espressif\esp32s3\esp32s3_common.dtsi:351 */
			interrupt-parent = < &intc >;       /* in zephyr\dts\xtensa\espressif\esp32s3\esp32s3_common.dtsi:352 */
			clocks = < &clock 0x73 >;           /* in zephyr\dts\xtensa\espressif\esp32s3\esp32s3_common.dtsi:353 */
			dma-host = < 0x0 >;                 /* in zephyr\dts\xtensa\espressif\esp32s3\esp32s3_common.dtsi:354 */
			#address-cells = < 0x1 >;           /* in zephyr\boards\espressif\esp32s3_devkitc\esp32s3_devkitc_procpu.dts:99 */
			#size-cells = < 0x0 >;              /* in zephyr\boards\espressif\esp32s3_devkitc\esp32s3_devkitc_procpu.dts:100 */
			status = "okay";                    /* in zephyr\boards\espressif\esp32s3_devkitc\esp32s3_devkitc_procpu.dts:101 */
			pinctrl-0 = < &spim2_default >;     /* in zephyr\boards\espressif\esp32s3_devkitc\esp32s3_devkitc_procpu.dts:102 */
			pinctrl-names = "default";          /* in zephyr\boards\espressif\esp32s3_devkitc\esp32s3_devkitc_procpu.dts:103 */
		};

		/* node '/soc/spi@60025000' defined in zephyr\dts\xtensa\espressif\esp32s3\esp32s3_common.dtsi:358 */
		spi3: spi@60025000 {
			compatible = "espressif,esp32-spi"; /* in zephyr\dts\xtensa\espressif\esp32s3\esp32s3_common.dtsi:359 */
			reg = < 0x60025000 0x1000 >;        /* in zephyr\dts\xtensa\espressif\esp32s3\esp32s3_common.dtsi:360 */
			interrupts = < 0x16 0x0 0x0 >;      /* in zephyr\dts\xtensa\espressif\esp32s3\esp32s3_common.dtsi:361 */
			interrupt-parent = < &intc >;       /* in zephyr\dts\xtensa\espressif\esp32s3\esp32s3_common.dtsi:362 */
			clocks = < &clock 0x74 >;           /* in zephyr\dts\xtensa\espressif\esp32s3\esp32s3_common.dtsi:363 */
			dma-host = < 0x1 >;                 /* in zephyr\dts\xtensa\espressif\esp32s3\esp32s3_common.dtsi:364 */
			#address-cells = < 0x1 >;           /* in zephyr\boards\espressif\esp32s3_devkitc\esp32s3_devkitc_procpu.dts:107 */
			#size-cells = < 0x0 >;              /* in zephyr\boards\espressif\esp32s3_devkitc\esp32s3_devkitc_procpu.dts:108 */
			status = "okay";                    /* in zephyr\boards\espressif\esp32s3_devkitc\esp32s3_devkitc_procpu.dts:109 */
			pinctrl-0 = < &spim3_default >;     /* in zephyr\boards\espressif\esp32s3_devkitc\esp32s3_devkitc_procpu.dts:110 */
			pinctrl-names = "default";          /* in zephyr\boards\espressif\esp32s3_devkitc\esp32s3_devkitc_procpu.dts:111 */
		};

		/* node '/soc/coretemp@60008800' defined in zephyr\dts\xtensa\espressif\esp32s3\esp32s3_common.dtsi:368 */
		coretemp: coretemp@60008800 {
			compatible = "espressif,esp32-temp"; /* in zephyr\dts\xtensa\espressif\esp32s3\esp32s3_common.dtsi:369 */
			friendly-name = "coretemp";          /* in zephyr\dts\xtensa\espressif\esp32s3\esp32s3_common.dtsi:370 */
			reg = < 0x60008800 0x4 >;            /* in zephyr\dts\xtensa\espressif\esp32s3\esp32s3_common.dtsi:371 */
			status = "disabled";                 /* in zephyr\dts\xtensa\espressif\esp32s3\esp32s3_common.dtsi:372 */
		};

		/* node '/soc/adc@60040000' defined in zephyr\dts\xtensa\espressif\esp32s3\esp32s3_common.dtsi:375 */
		adc0: adc@60040000 {
			compatible = "espressif,esp32-adc"; /* in zephyr\dts\xtensa\espressif\esp32s3\esp32s3_common.dtsi:376 */
			reg = < 0x60040000 0x4 >;           /* in zephyr\dts\xtensa\espressif\esp32s3\esp32s3_common.dtsi:377 */
			clocks = < &clock 0x80 >;           /* in zephyr\dts\xtensa\espressif\esp32s3\esp32s3_common.dtsi:378 */
			unit = < 0x1 >;                     /* in zephyr\dts\xtensa\espressif\esp32s3\esp32s3_common.dtsi:379 */
			channel-count = < 0xa >;            /* in zephyr\dts\xtensa\espressif\esp32s3\esp32s3_common.dtsi:380 */
			#io-channel-cells = < 0x1 >;        /* in zephyr\dts\xtensa\espressif\esp32s3\esp32s3_common.dtsi:381 */
			status = "disabled";                /* in zephyr\dts\xtensa\espressif\esp32s3\esp32s3_common.dtsi:382 */
		};

		/* node '/soc/adc@60040004' defined in zephyr\dts\xtensa\espressif\esp32s3\esp32s3_common.dtsi:385 */
		adc1: adc@60040004 {
			compatible = "espressif,esp32-adc"; /* in zephyr\dts\xtensa\espressif\esp32s3\esp32s3_common.dtsi:386 */
			reg = < 0x60040004 0x4 >;           /* in zephyr\dts\xtensa\espressif\esp32s3\esp32s3_common.dtsi:387 */
			clocks = < &clock 0x80 >;           /* in zephyr\dts\xtensa\espressif\esp32s3\esp32s3_common.dtsi:388 */
			unit = < 0x2 >;                     /* in zephyr\dts\xtensa\espressif\esp32s3\esp32s3_common.dtsi:389 */
			channel-count = < 0xa >;            /* in zephyr\dts\xtensa\espressif\esp32s3\esp32s3_common.dtsi:390 */
			#io-channel-cells = < 0x1 >;        /* in zephyr\dts\xtensa\espressif\esp32s3\esp32s3_common.dtsi:391 */
			status = "disabled";                /* in zephyr\dts\xtensa\espressif\esp32s3\esp32s3_common.dtsi:392 */
		};

		/* node '/soc/can@6002b000' defined in zephyr\dts\xtensa\espressif\esp32s3\esp32s3_common.dtsi:395 */
		twai: can@6002b000 {
			compatible = "espressif,esp32-twai"; /* in zephyr\dts\xtensa\espressif\esp32s3\esp32s3_common.dtsi:396 */
			reg = < 0x6002b000 0x1000 >;         /* in zephyr\dts\xtensa\espressif\esp32s3\esp32s3_common.dtsi:397 */
			interrupts = < 0x25 0x0 0x0 >;       /* in zephyr\dts\xtensa\espressif\esp32s3\esp32s3_common.dtsi:398 */
			interrupt-parent = < &intc >;        /* in zephyr\dts\xtensa\espressif\esp32s3\esp32s3_common.dtsi:399 */
			clocks = < &clock 0x76 >;            /* in zephyr\dts\xtensa\espressif\esp32s3\esp32s3_common.dtsi:400 */
			status = "disabled";                 /* in zephyr\dts\xtensa\espressif\esp32s3\esp32s3_common.dtsi:401 */
			pinctrl-0 = < &twai_default >;       /* in zephyr\boards\espressif\esp32s3_devkitc\esp32s3_devkitc_procpu.dts:115 */
			pinctrl-names = "default";           /* in zephyr\boards\espressif\esp32s3_devkitc\esp32s3_devkitc_procpu.dts:116 */
		};

		/* node '/soc/lcd_cam@60041000' defined in zephyr\dts\xtensa\espressif\esp32s3\esp32s3_common.dtsi:404 */
		lcd_cam: lcd_cam@60041000 {
			compatible = "espressif,esp32-lcd-cam"; /* in zephyr\dts\xtensa\espressif\esp32s3\esp32s3_common.dtsi:405 */
			reg = < 0x60041000 0x1000 >;            /* in zephyr\dts\xtensa\espressif\esp32s3\esp32s3_common.dtsi:406 */
			clocks = < &clock 0x2 >;                /* in zephyr\dts\xtensa\espressif\esp32s3\esp32s3_common.dtsi:407 */
			interrupts = < 0x18 0x0 0x0 >;          /* in zephyr\dts\xtensa\espressif\esp32s3\esp32s3_common.dtsi:408 */
			interrupt-parent = < &intc >;           /* in zephyr\dts\xtensa\espressif\esp32s3\esp32s3_common.dtsi:409 */
			dmas = < &dma 0x6 >,
			       < &dma 0x7 >;                    /* in zephyr\dts\xtensa\espressif\esp32s3\esp32s3_common.dtsi:410 */
			dma-names = "rx",
			            "tx";                       /* in zephyr\dts\xtensa\espressif\esp32s3\esp32s3_common.dtsi:411 */

			/* node '/soc/lcd_cam@60041000/lcd_cam_dvp' defined in zephyr\dts\xtensa\espressif\esp32s3\esp32s3_common.dtsi:413 */
			lcd_cam_dvp: lcd_cam_dvp {
				compatible = "espressif,esp32-lcd-cam-dvp"; /* in zephyr\dts\xtensa\espressif\esp32s3\esp32s3_common.dtsi:414 */
				status = "disabled";                        /* in zephyr\dts\xtensa\espressif\esp32s3\esp32s3_common.dtsi:415 */
			};

			/* node '/soc/lcd_cam@60041000/lcd_cam_disp' defined in zephyr\dts\xtensa\espressif\esp32s3\esp32s3_common.dtsi:418 */
			lcd_cam_disp: lcd_cam_disp {
				compatible = "espressif,esp32-lcd-cam-mipi-dbi"; /* in zephyr\dts\xtensa\espressif\esp32s3\esp32s3_common.dtsi:419 */
				#address-cells = < 0x1 >;                        /* in zephyr\dts\xtensa\espressif\esp32s3\esp32s3_common.dtsi:420 */
				#size-cells = < 0x0 >;                           /* in zephyr\dts\xtensa\espressif\esp32s3\esp32s3_common.dtsi:421 */
				status = "disabled";                             /* in zephyr\dts\xtensa\espressif\esp32s3\esp32s3_common.dtsi:422 */
			};
		};

		/* node '/soc/uart@60038000' defined in zephyr\dts\xtensa\espressif\esp32s3\esp32s3_common.dtsi:426 */
		usb_serial: uart@60038000 {
			compatible = "espressif,esp32-usb-serial"; /* in zephyr\dts\xtensa\espressif\esp32s3\esp32s3_common.dtsi:427 */
			reg = < 0x60038000 0x1000 >;               /* in zephyr\dts\xtensa\espressif\esp32s3\esp32s3_common.dtsi:428 */
			interrupts = < 0x60 0x0 0x0 >;             /* in zephyr\dts\xtensa\espressif\esp32s3\esp32s3_common.dtsi:430 */
			interrupt-parent = < &intc >;              /* in zephyr\dts\xtensa\espressif\esp32s3\esp32s3_common.dtsi:431 */
			clocks = < &clock 0x66 >;                  /* in zephyr\dts\xtensa\espressif\esp32s3\esp32s3_common.dtsi:432 */
			status = "disabled";                       /* in zephyr\boards\espressif\esp32s3_devkitc\esp32s3_devkitc_procpu.dts:46 */
		};

		/* node '/soc/usb_otg@60080000' defined in zephyr\dts\xtensa\espressif\esp32s3\esp32s3_common.dtsi:435 */
		usb_otg: zephyr_udc0: usb_otg@60080000 {
			compatible = "espressif,esp32-usb-otg",
			             "snps,dwc2";               /* in zephyr\dts\xtensa\espressif\esp32s3\esp32s3_common.dtsi:436 */
			reg = < 0x60080000 0x40000 >;           /* in zephyr\dts\xtensa\espressif\esp32s3\esp32s3_common.dtsi:437 */
			interrupts = < 0x26 0x0 0x0 >;          /* in zephyr\dts\xtensa\espressif\esp32s3\esp32s3_common.dtsi:439 */
			interrupt-parent = < &intc >;           /* in zephyr\dts\xtensa\espressif\esp32s3\esp32s3_common.dtsi:440 */
			clocks = < &clock 0x66 >;               /* in zephyr\dts\xtensa\espressif\esp32s3\esp32s3_common.dtsi:441 */
			num-out-eps = < 0x6 >;                  /* in zephyr\dts\xtensa\espressif\esp32s3\esp32s3_common.dtsi:442 */
			num-in-eps = < 0x6 >;                   /* in zephyr\dts\xtensa\espressif\esp32s3\esp32s3_common.dtsi:443 */
			ghwcfg1 = < 0x0 >;                      /* in zephyr\dts\xtensa\espressif\esp32s3\esp32s3_common.dtsi:444 */
			ghwcfg2 = < 0x224dd930 >;               /* in zephyr\dts\xtensa\espressif\esp32s3\esp32s3_common.dtsi:445 */
			ghwcfg4 = < 0xd3f0a030 >;               /* in zephyr\dts\xtensa\espressif\esp32s3\esp32s3_common.dtsi:446 */
			status = "okay";                        /* in zephyr\boards\espressif\esp32s3_devkitc\esp32s3_devkitc_procpu.dts:152 */
		};

		/* node '/soc/counter@6001f000' defined in zephyr\dts\xtensa\espressif\esp32s3\esp32s3_common.dtsi:449 */
		timer0: counter@6001f000 {
			compatible = "espressif,esp32-timer"; /* in zephyr\dts\xtensa\espressif\esp32s3\esp32s3_common.dtsi:450 */
			reg = < 0x6001f000 0x1000 >;          /* in zephyr\dts\xtensa\espressif\esp32s3\esp32s3_common.dtsi:451 */
			clocks = < &clock 0x3 >;              /* in zephyr\dts\xtensa\espressif\esp32s3\esp32s3_common.dtsi:452 */
			group = < 0x0 >;                      /* in zephyr\dts\xtensa\espressif\esp32s3\esp32s3_common.dtsi:453 */
			index = < 0x0 >;                      /* in zephyr\dts\xtensa\espressif\esp32s3\esp32s3_common.dtsi:454 */
			interrupts = < 0x32 0x0 0x0 >;        /* in zephyr\dts\xtensa\espressif\esp32s3\esp32s3_common.dtsi:455 */
			interrupt-parent = < &intc >;         /* in zephyr\dts\xtensa\espressif\esp32s3\esp32s3_common.dtsi:456 */
			status = "disabled";                  /* in zephyr\boards\espressif\esp32s3_devkitc\esp32s3_devkitc_procpu.dts:120 */

			/* node '/soc/counter@6001f000/counter' defined in zephyr\dts\xtensa\espressif\esp32s3\esp32s3_common.dtsi:459 */
			counter {
				compatible = "espressif,esp32-counter"; /* in zephyr\dts\xtensa\espressif\esp32s3\esp32s3_common.dtsi:460 */
				status = "disabled";                    /* in zephyr\dts\xtensa\espressif\esp32s3\esp32s3_common.dtsi:461 */
			};
		};

		/* node '/soc/counter@6001f024' defined in zephyr\dts\xtensa\espressif\esp32s3\esp32s3_common.dtsi:465 */
		timer1: counter@6001f024 {
			compatible = "espressif,esp32-timer"; /* in zephyr\dts\xtensa\espressif\esp32s3\esp32s3_common.dtsi:466 */
			reg = < 0x6001f024 0x1000 >;          /* in zephyr\dts\xtensa\espressif\esp32s3\esp32s3_common.dtsi:467 */
			clocks = < &clock 0x3 >;              /* in zephyr\dts\xtensa\espressif\esp32s3\esp32s3_common.dtsi:468 */
			group = < 0x0 >;                      /* in zephyr\dts\xtensa\espressif\esp32s3\esp32s3_common.dtsi:469 */
			index = < 0x1 >;                      /* in zephyr\dts\xtensa\espressif\esp32s3\esp32s3_common.dtsi:470 */
			interrupts = < 0x33 0x0 0x0 >;        /* in zephyr\dts\xtensa\espressif\esp32s3\esp32s3_common.dtsi:471 */
			interrupt-parent = < &intc >;         /* in zephyr\dts\xtensa\espressif\esp32s3\esp32s3_common.dtsi:472 */
			status = "disabled";                  /* in zephyr\boards\espressif\esp32s3_devkitc\esp32s3_devkitc_procpu.dts:124 */

			/* node '/soc/counter@6001f024/counter' defined in zephyr\dts\xtensa\espressif\esp32s3\esp32s3_common.dtsi:475 */
			counter {
				compatible = "espressif,esp32-counter"; /* in zephyr\dts\xtensa\espressif\esp32s3\esp32s3_common.dtsi:476 */
				status = "disabled";                    /* in zephyr\dts\xtensa\espressif\esp32s3\esp32s3_common.dtsi:477 */
			};
		};

		/* node '/soc/counter@60020000' defined in zephyr\dts\xtensa\espressif\esp32s3\esp32s3_common.dtsi:481 */
		timer2: counter@60020000 {
			compatible = "espressif,esp32-timer"; /* in zephyr\dts\xtensa\espressif\esp32s3\esp32s3_common.dtsi:482 */
			reg = < 0x60020000 0x1000 >;          /* in zephyr\dts\xtensa\espressif\esp32s3\esp32s3_common.dtsi:483 */
			clocks = < &clock 0x4 >;              /* in zephyr\dts\xtensa\espressif\esp32s3\esp32s3_common.dtsi:484 */
			group = < 0x1 >;                      /* in zephyr\dts\xtensa\espressif\esp32s3\esp32s3_common.dtsi:485 */
			index = < 0x0 >;                      /* in zephyr\dts\xtensa\espressif\esp32s3\esp32s3_common.dtsi:486 */
			interrupts = < 0x35 0x0 0x0 >;        /* in zephyr\dts\xtensa\espressif\esp32s3\esp32s3_common.dtsi:487 */
			interrupt-parent = < &intc >;         /* in zephyr\dts\xtensa\espressif\esp32s3\esp32s3_common.dtsi:488 */
			status = "disabled";                  /* in zephyr\boards\espressif\esp32s3_devkitc\esp32s3_devkitc_procpu.dts:128 */

			/* node '/soc/counter@60020000/counter' defined in zephyr\dts\xtensa\espressif\esp32s3\esp32s3_common.dtsi:491 */
			counter {
				compatible = "espressif,esp32-counter"; /* in zephyr\dts\xtensa\espressif\esp32s3\esp32s3_common.dtsi:492 */
				status = "disabled";                    /* in zephyr\dts\xtensa\espressif\esp32s3\esp32s3_common.dtsi:493 */
			};
		};

		/* node '/soc/counter@60020024' defined in zephyr\dts\xtensa\espressif\esp32s3\esp32s3_common.dtsi:497 */
		timer3: counter@60020024 {
			compatible = "espressif,esp32-timer"; /* in zephyr\dts\xtensa\espressif\esp32s3\esp32s3_common.dtsi:498 */
			reg = < 0x60020024 0x1000 >;          /* in zephyr\dts\xtensa\espressif\esp32s3\esp32s3_common.dtsi:499 */
			clocks = < &clock 0x4 >;              /* in zephyr\dts\xtensa\espressif\esp32s3\esp32s3_common.dtsi:500 */
			group = < 0x1 >;                      /* in zephyr\dts\xtensa\espressif\esp32s3\esp32s3_common.dtsi:501 */
			index = < 0x1 >;                      /* in zephyr\dts\xtensa\espressif\esp32s3\esp32s3_common.dtsi:502 */
			interrupts = < 0x36 0x0 0x0 >;        /* in zephyr\dts\xtensa\espressif\esp32s3\esp32s3_common.dtsi:503 */
			interrupt-parent = < &intc >;         /* in zephyr\dts\xtensa\espressif\esp32s3\esp32s3_common.dtsi:504 */
			status = "disabled";                  /* in zephyr\boards\espressif\esp32s3_devkitc\esp32s3_devkitc_procpu.dts:132 */

			/* node '/soc/counter@60020024/counter' defined in zephyr\dts\xtensa\espressif\esp32s3\esp32s3_common.dtsi:506 */
			counter {
				compatible = "espressif,esp32-counter"; /* in zephyr\dts\xtensa\espressif\esp32s3\esp32s3_common.dtsi:507 */
				status = "disabled";                    /* in zephyr\dts\xtensa\espressif\esp32s3\esp32s3_common.dtsi:508 */
			};
		};

		/* node '/soc/watchdog@6001f048' defined in zephyr\dts\xtensa\espressif\esp32s3\esp32s3_common.dtsi:512 */
		wdt0: watchdog@6001f048 {
			compatible = "espressif,esp32-watchdog"; /* in zephyr\dts\xtensa\espressif\esp32s3\esp32s3_common.dtsi:513 */
			reg = < 0x6001f048 0x20 >;               /* in zephyr\dts\xtensa\espressif\esp32s3\esp32s3_common.dtsi:514 */
			interrupts = < 0x34 0x0 0x0 >;           /* in zephyr\dts\xtensa\espressif\esp32s3\esp32s3_common.dtsi:515 */
			interrupt-parent = < &intc >;            /* in zephyr\dts\xtensa\espressif\esp32s3\esp32s3_common.dtsi:516 */
			clocks = < &clock 0x3 >;                 /* in zephyr\dts\xtensa\espressif\esp32s3\esp32s3_common.dtsi:517 */
			status = "okay";                         /* in zephyr\boards\espressif\esp32s3_devkitc\esp32s3_devkitc_procpu.dts:136 */
		};

		/* node '/soc/watchdog@60020048' defined in zephyr\dts\xtensa\espressif\esp32s3\esp32s3_common.dtsi:521 */
		wdt1: watchdog@60020048 {
			compatible = "espressif,esp32-watchdog"; /* in zephyr\dts\xtensa\espressif\esp32s3\esp32s3_common.dtsi:522 */
			reg = < 0x60020048 0x20 >;               /* in zephyr\dts\xtensa\espressif\esp32s3\esp32s3_common.dtsi:523 */
			interrupts = < 0x37 0x0 0x0 >;           /* in zephyr\dts\xtensa\espressif\esp32s3\esp32s3_common.dtsi:524 */
			interrupt-parent = < &intc >;            /* in zephyr\dts\xtensa\espressif\esp32s3\esp32s3_common.dtsi:525 */
			clocks = < &clock 0x4 >;                 /* in zephyr\dts\xtensa\espressif\esp32s3\esp32s3_common.dtsi:526 */
			status = "disabled";                     /* in zephyr\dts\xtensa\espressif\esp32s3\esp32s3_common.dtsi:527 */
		};

		/* node '/soc/trng@6003507c' defined in zephyr\dts\xtensa\espressif\esp32s3\esp32s3_common.dtsi:530 */
		trng0: trng@6003507c {
			compatible = "espressif,esp32-trng"; /* in zephyr\dts\xtensa\espressif\esp32s3\esp32s3_common.dtsi:531 */
			reg = < 0x6003507c 0x4 >;            /* in zephyr\dts\xtensa\espressif\esp32s3\esp32s3_common.dtsi:532 */
			clocks = < &clock 0x6 >;             /* in zephyr\dts\xtensa\espressif\esp32s3\esp32s3_common.dtsi:533 */
			status = "okay";                     /* in zephyr\boards\espressif\esp32s3_devkitc\esp32s3_devkitc_procpu.dts:140 */
		};

		/* node '/soc/ledc@60019000' defined in zephyr\dts\xtensa\espressif\esp32s3\esp32s3_common.dtsi:537 */
		ledc0: ledc@60019000 {
			compatible = "espressif,esp32-ledc"; /* in zephyr\dts\xtensa\espressif\esp32s3\esp32s3_common.dtsi:538 */
			#pwm-cells = < 0x3 >;                /* in zephyr\dts\xtensa\espressif\esp32s3\esp32s3_common.dtsi:539 */
			reg = < 0x60019000 0x1000 >;         /* in zephyr\dts\xtensa\espressif\esp32s3\esp32s3_common.dtsi:540 */
			clocks = < &clock 0x64 >;            /* in zephyr\dts\xtensa\espressif\esp32s3\esp32s3_common.dtsi:541 */
			status = "disabled";                 /* in zephyr\dts\xtensa\espressif\esp32s3\esp32s3_common.dtsi:542 */
		};

		/* node '/soc/mcpwm@6001e000' defined in zephyr\dts\xtensa\espressif\esp32s3\esp32s3_common.dtsi:545 */
		mcpwm0: mcpwm@6001e000 {
			compatible = "espressif,esp32-mcpwm"; /* in zephyr\dts\xtensa\espressif\esp32s3\esp32s3_common.dtsi:546 */
			reg = < 0x6001e000 0x1000 >;          /* in zephyr\dts\xtensa\espressif\esp32s3\esp32s3_common.dtsi:547 */
			interrupts = < 0x1f 0x0 0x0 >;        /* in zephyr\dts\xtensa\espressif\esp32s3\esp32s3_common.dtsi:548 */
			interrupt-parent = < &intc >;         /* in zephyr\dts\xtensa\espressif\esp32s3\esp32s3_common.dtsi:549 */
			clocks = < &clock 0x6b >;             /* in zephyr\dts\xtensa\espressif\esp32s3\esp32s3_common.dtsi:550 */
			#pwm-cells = < 0x3 >;                 /* in zephyr\dts\xtensa\espressif\esp32s3\esp32s3_common.dtsi:551 */
			status = "disabled";                  /* in zephyr\dts\xtensa\espressif\esp32s3\esp32s3_common.dtsi:552 */
		};

		/* node '/soc/mcpwm@6002c000' defined in zephyr\dts\xtensa\espressif\esp32s3\esp32s3_common.dtsi:555 */
		mcpwm1: mcpwm@6002c000 {
			compatible = "espressif,esp32-mcpwm"; /* in zephyr\dts\xtensa\espressif\esp32s3\esp32s3_common.dtsi:556 */
			reg = < 0x6002c000 0x1000 >;          /* in zephyr\dts\xtensa\espressif\esp32s3\esp32s3_common.dtsi:557 */
			interrupts = < 0x20 0x0 0x0 >;        /* in zephyr\dts\xtensa\espressif\esp32s3\esp32s3_common.dtsi:558 */
			interrupt-parent = < &intc >;         /* in zephyr\dts\xtensa\espressif\esp32s3\esp32s3_common.dtsi:559 */
			clocks = < &clock 0x6c >;             /* in zephyr\dts\xtensa\espressif\esp32s3\esp32s3_common.dtsi:560 */
			#pwm-cells = < 0x3 >;                 /* in zephyr\dts\xtensa\espressif\esp32s3\esp32s3_common.dtsi:561 */
			status = "disabled";                  /* in zephyr\dts\xtensa\espressif\esp32s3\esp32s3_common.dtsi:562 */
		};

		/* node '/soc/pcnt@60017000' defined in zephyr\dts\xtensa\espressif\esp32s3\esp32s3_common.dtsi:565 */
		pcnt: pcnt@60017000 {
			compatible = "espressif,esp32-pcnt"; /* in zephyr\dts\xtensa\espressif\esp32s3\esp32s3_common.dtsi:566 */
			reg = < 0x60017000 0x1000 >;         /* in zephyr\dts\xtensa\espressif\esp32s3\esp32s3_common.dtsi:567 */
			interrupts = < 0x29 0x0 0x0 >;       /* in zephyr\dts\xtensa\espressif\esp32s3\esp32s3_common.dtsi:568 */
			interrupt-parent = < &intc >;        /* in zephyr\dts\xtensa\espressif\esp32s3\esp32s3_common.dtsi:569 */
			clocks = < &clock 0x71 >;            /* in zephyr\dts\xtensa\espressif\esp32s3\esp32s3_common.dtsi:570 */
			status = "disabled";                 /* in zephyr\dts\xtensa\espressif\esp32s3\esp32s3_common.dtsi:571 */
		};

		/* node '/soc/dma@6003f000' defined in zephyr\dts\xtensa\espressif\esp32s3\esp32s3_common.dtsi:574 */
		dma: dma@6003f000 {
			compatible = "espressif,esp32-gdma"; /* in zephyr\dts\xtensa\espressif\esp32s3\esp32s3_common.dtsi:575 */
			reg = < 0x6003f000 0x1000 >;         /* in zephyr\dts\xtensa\espressif\esp32s3\esp32s3_common.dtsi:576 */
			#dma-cells = < 0x1 >;                /* in zephyr\dts\xtensa\espressif\esp32s3\esp32s3_common.dtsi:577 */
			interrupts = < 0x42 0x0 0x100 >,
			             < 0x47 0x0 0x100 >,
			             < 0x43 0x0 0x100 >,
			             < 0x48 0x0 0x100 >,
			             < 0x44 0x0 0x100 >,
			             < 0x49 0x0 0x100 >,
			             < 0x45 0x0 0x100 >,
			             < 0x4a 0x0 0x100 >,
			             < 0x46 0x0 0x100 >,
			             < 0x4b 0x0 0x100 >;     /* in zephyr\dts\xtensa\espressif\esp32s3\esp32s3_common.dtsi:578 */
			interrupt-parent = < &intc >;        /* in zephyr\dts\xtensa\espressif\esp32s3\esp32s3_common.dtsi:598 */
			clocks = < &clock 0x7e >;            /* in zephyr\dts\xtensa\espressif\esp32s3\esp32s3_common.dtsi:599 */
			dma-channels = < 0xa >;              /* in zephyr\dts\xtensa\espressif\esp32s3\esp32s3_common.dtsi:600 */
			dma-buf-addr-alignment = < 0x4 >;    /* in zephyr\dts\xtensa\espressif\esp32s3\esp32s3_common.dtsi:601 */
			status = "disabled";                 /* in zephyr\dts\xtensa\espressif\esp32s3\esp32s3_common.dtsi:602 */
			phandle = < 0x9 >;                   /* in zephyr\dts\xtensa\espressif\esp32s3\esp32s3_common.dtsi:328 */
		};

		/* node '/soc/sdhc@60028000' defined in zephyr\dts\xtensa\espressif\esp32s3\esp32s3_common.dtsi:605 */
		sdhc: sdhc@60028000 {
			compatible = "espressif,esp32-sdhc"; /* in zephyr\dts\xtensa\espressif\esp32s3\esp32s3_common.dtsi:606 */
			reg = < 0x60028000 0x1000 >;         /* in zephyr\dts\xtensa\espressif\esp32s3\esp32s3_common.dtsi:607 */
			interrupts = < 0x1e 0x0 0x0 >;       /* in zephyr\dts\xtensa\espressif\esp32s3\esp32s3_common.dtsi:608 */
			interrupt-parent = < &intc >;        /* in zephyr\dts\xtensa\espressif\esp32s3\esp32s3_common.dtsi:609 */
			clocks = < &clock 0x75 >;            /* in zephyr\dts\xtensa\espressif\esp32s3\esp32s3_common.dtsi:610 */
			#address-cells = < 0x1 >;            /* in zephyr\dts\xtensa\espressif\esp32s3\esp32s3_common.dtsi:611 */
			#size-cells = < 0x0 >;               /* in zephyr\dts\xtensa\espressif\esp32s3\esp32s3_common.dtsi:612 */

			/* node '/soc/sdhc@60028000/sdhc@0' defined in zephyr\dts\xtensa\espressif\esp32s3\esp32s3_common.dtsi:614 */
			sdhc0: sdhc@0 {
				compatible = "espressif,esp32-sdhc-slot"; /* in zephyr\dts\xtensa\espressif\esp32s3\esp32s3_common.dtsi:615 */
				reg = < 0x0 >;                            /* in zephyr\dts\xtensa\espressif\esp32s3\esp32s3_common.dtsi:616 */
				status = "disabled";                      /* in zephyr\dts\xtensa\espressif\esp32s3\esp32s3_common.dtsi:617 */
			};

			/* node '/soc/sdhc@60028000/sdhc@1' defined in zephyr\dts\xtensa\espressif\esp32s3\esp32s3_common.dtsi:620 */
			sdhc1: sdhc@1 {
				compatible = "espressif,esp32-sdhc-slot"; /* in zephyr\dts\xtensa\espressif\esp32s3\esp32s3_common.dtsi:621 */
				reg = < 0x1 >;                            /* in zephyr\dts\xtensa\espressif\esp32s3\esp32s3_common.dtsi:622 */
				status = "disabled";                      /* in zephyr\dts\xtensa\espressif\esp32s3\esp32s3_common.dtsi:623 */
			};
		};

		/* node '/soc/sha@6003b000' defined in zephyr\dts\xtensa\espressif\esp32s3\esp32s3_common.dtsi:627 */
		sha: sha@6003b000 {
			compatible = "espressif,esp32-sha"; /* in zephyr\dts\xtensa\espressif\esp32s3\esp32s3_common.dtsi:628 */
			reg = < 0x6003b000 0x100 >;         /* in zephyr\dts\xtensa\espressif\esp32s3\esp32s3_common.dtsi:629 */
			clocks = < &clock 0x7a >;           /* in zephyr\dts\xtensa\espressif\esp32s3\esp32s3_common.dtsi:630 */
			status = "okay";                    /* in zephyr\dts\xtensa\espressif\esp32s3\esp32s3_common.dtsi:631 */
		};

		/* node '/soc/aes@6003a000' defined in zephyr\dts\xtensa\espressif\esp32s3\esp32s3_common.dtsi:634 */
		aes: aes@6003a000 {
			compatible = "espressif,esp32-aes"; /* in zephyr\dts\xtensa\espressif\esp32s3\esp32s3_common.dtsi:635 */
			reg = < 0x6003a000 0x1000 >;        /* in zephyr\dts\xtensa\espressif\esp32s3\esp32s3_common.dtsi:636 */
			clocks = < &clock 0x79 >;           /* in zephyr\dts\xtensa\espressif\esp32s3\esp32s3_common.dtsi:637 */
			status = "okay";                    /* in zephyr\dts\xtensa\espressif\esp32s3\esp32s3_common.dtsi:638 */
		};
	};

	/* node '/cpus' defined in zephyr\dts\xtensa\espressif\esp32s3\esp32s3_common.dtsi:28 */
	cpus {
		#address-cells = < 0x1 >; /* in zephyr\dts\xtensa\espressif\esp32s3\esp32s3_common.dtsi:29 */
		#size-cells = < 0x0 >;    /* in zephyr\dts\xtensa\espressif\esp32s3\esp32s3_common.dtsi:30 */

		/* node '/cpus/cpu@0' defined in zephyr\dts\xtensa\espressif\esp32s3\esp32s3_common.dtsi:32 */
		cpu0: cpu@0 {
			device_type = "cpu";                             /* in zephyr\dts\xtensa\espressif\esp32s3\esp32s3_common.dtsi:33 */
			compatible = "espressif,xtensa-lx7";             /* in zephyr\dts\xtensa\espressif\esp32s3\esp32s3_common.dtsi:34 */
			reg = < 0x0 >;                                   /* in zephyr\dts\xtensa\espressif\esp32s3\esp32s3_common.dtsi:35 */
			cpu-power-states = < &light_sleep &deep_sleep >; /* in zephyr\dts\xtensa\espressif\esp32s3\esp32s3_common.dtsi:36 */
			clock-source = < 0x1 >;                          /* in zephyr\dts\xtensa\espressif\esp32s3\esp32s3_common.dtsi:37 */
			clock-frequency = < 0xe4e1c00 >;                 /* in zephyr\dts\xtensa\espressif\esp32s3\esp32s3_common.dtsi:38 */
			xtal-freq = < 0x2625a00 >;                       /* in zephyr\dts\xtensa\espressif\esp32s3\esp32s3_common.dtsi:39 */
			d-cache-line-size = < 0x10 >;                    /* in zephyr\dts\xtensa\espressif\esp32s3\esp32s3_common.dtsi:40 */
		};

		/* node '/cpus/cpu@1' defined in zephyr\dts\xtensa\espressif\esp32s3\esp32s3_common.dtsi:43 */
		cpu1: cpu@1 {
			device_type = "cpu";                 /* in zephyr\dts\xtensa\espressif\esp32s3\esp32s3_common.dtsi:44 */
			compatible = "espressif,xtensa-lx7"; /* in zephyr\dts\xtensa\espressif\esp32s3\esp32s3_common.dtsi:45 */
			reg = < 0x1 >;                       /* in zephyr\dts\xtensa\espressif\esp32s3\esp32s3_common.dtsi:46 */
			clock-source = < 0x1 >;              /* in zephyr\dts\xtensa\espressif\esp32s3\esp32s3_common.dtsi:47 */
			clock-frequency = < 0xe4e1c00 >;     /* in zephyr\dts\xtensa\espressif\esp32s3\esp32s3_common.dtsi:48 */
			xtal-freq = < 0x2625a00 >;           /* in zephyr\dts\xtensa\espressif\esp32s3\esp32s3_common.dtsi:49 */
			d-cache-line-size = < 0x10 >;        /* in zephyr\dts\xtensa\espressif\esp32s3\esp32s3_common.dtsi:50 */
		};

		/* node '/cpus/power-states' defined in zephyr\dts\xtensa\espressif\esp32s3\esp32s3_common.dtsi:53 */
		power-states {

			/* node '/cpus/power-states/light_sleep' defined in zephyr\dts\xtensa\espressif\esp32s3\esp32s3_common.dtsi:54 */
			light_sleep: light_sleep {
				compatible = "zephyr,power-state"; /* in zephyr\dts\xtensa\espressif\esp32s3\esp32s3_common.dtsi:55 */
				power-state-name = "standby";      /* in zephyr\dts\xtensa\espressif\esp32s3\esp32s3_common.dtsi:56 */
				min-residency-us = < 0x3e8 >;      /* in zephyr\dts\xtensa\espressif\esp32s3\esp32s3_common.dtsi:57 */
				exit-latency-us = < 0x32 >;        /* in zephyr\dts\xtensa\espressif\esp32s3\esp32s3_common.dtsi:58 */
				phandle = < 0xf >;                 /* in zephyr\dts\xtensa\espressif\esp32s3\esp32s3_common.dtsi:36 */
			};

			/* node '/cpus/power-states/deep_sleep' defined in zephyr\dts\xtensa\espressif\esp32s3\esp32s3_common.dtsi:61 */
			deep_sleep: deep_sleep {
				compatible = "zephyr,power-state"; /* in zephyr\dts\xtensa\espressif\esp32s3\esp32s3_common.dtsi:65 */
				power-state-name = "soft-off";     /* in zephyr\dts\xtensa\espressif\esp32s3\esp32s3_common.dtsi:66 */
				status = "disabled";               /* in zephyr\dts\xtensa\espressif\esp32s3\esp32s3_common.dtsi:67 */
				phandle = < 0x10 >;                /* in zephyr\dts\xtensa\espressif\esp32s3\esp32s3_common.dtsi:36 */
			};
		};
	};

	/* node '/wifi' defined in zephyr\dts\xtensa\espressif\esp32s3\esp32s3_common.dtsi:72 */
	wifi: wifi {
		compatible = "espressif,esp32-wifi"; /* in zephyr\dts\xtensa\espressif\esp32s3\esp32s3_common.dtsi:73 */
		status = "okay";                     /* in zephyr\boards\espressif\esp32s3_devkitc\esp32s3_devkitc_procpu.dts:148 */
	};

	/* node '/esp32_bt_hci' defined in zephyr\dts\xtensa\espressif\esp32s3\esp32s3_common.dtsi:77 */
	esp32_bt_hci: esp32_bt_hci {
		compatible = "espressif,esp32-bt-hci"; /* in zephyr\dts\xtensa\espressif\esp32s3\esp32s3_common.dtsi:78 */
		bt-hci-vs-ext;                         /* in zephyr\dts\xtensa\espressif\esp32s3\esp32s3_common.dtsi:79 */
		status = "okay";                       /* in zephyr\boards\espressif\esp32s3_devkitc\esp32s3_devkitc_procpu.dts:144 */
	};

	/* node '/pin-controller' defined in zephyr\dts\xtensa\espressif\esp32s3\esp32s3_common.dtsi:83 */
	pinctrl: pin-controller {
		compatible = "espressif,esp32-pinctrl"; /* in zephyr\dts\xtensa\espressif\esp32s3\esp32s3_common.dtsi:84 */
		status = "okay";                        /* in zephyr\dts\xtensa\espressif\esp32s3\esp32s3_common.dtsi:85 */

		/* node '/pin-controller/uart0_default' defined in zephyr\boards\espressif\esp32s3_devkitc\esp32s3_devkitc-pinctrl.dtsi:10 */
		uart0_default: uart0_default {
			phandle = < 0x4 >; /* in zephyr\boards\espressif\esp32s3_devkitc\esp32s3_devkitc_procpu.dts:52 */

			/* node '/pin-controller/uart0_default/group1' defined in zephyr\boards\espressif\esp32s3_devkitc\esp32s3_devkitc-pinctrl.dtsi:11 */
			group1 {
				pinmux = < 0x67feb >; /* in zephyr\boards\espressif\esp32s3_devkitc\esp32s3_devkitc-pinctrl.dtsi:12 */
				output-high;          /* in zephyr\boards\espressif\esp32s3_devkitc\esp32s3_devkitc-pinctrl.dtsi:13 */
			};

			/* node '/pin-controller/uart0_default/group2' defined in zephyr\boards\espressif\esp32s3_devkitc\esp32s3_devkitc-pinctrl.dtsi:16 */
			group2 {
				pinmux = < 0xff832c >; /* in zephyr\boards\espressif\esp32s3_devkitc\esp32s3_devkitc-pinctrl.dtsi:17 */
				bias-pull-up;          /* in zephyr\boards\espressif\esp32s3_devkitc\esp32s3_devkitc-pinctrl.dtsi:18 */
			};
		};

		/* node '/pin-controller/uart1_default' defined in zephyr\boards\espressif\esp32s3_devkitc\esp32s3_devkitc-pinctrl.dtsi:22 */
		uart1_default: uart1_default {

			/* node '/pin-controller/uart1_default/group1' defined in zephyr\boards\espressif\esp32s3_devkitc\esp32s3_devkitc-pinctrl.dtsi:23 */
			group1 {
				pinmux = < 0x7ffd1 >; /* in zephyr\boards\espressif\esp32s3_devkitc\esp32s3_devkitc-pinctrl.dtsi:24 */
				output-high;          /* in zephyr\boards\espressif\esp32s3_devkitc\esp32s3_devkitc-pinctrl.dtsi:25 */
			};

			/* node '/pin-controller/uart1_default/group2' defined in zephyr\boards\espressif\esp32s3_devkitc\esp32s3_devkitc-pinctrl.dtsi:28 */
			group2 {
				pinmux = < 0xff83d2 >; /* in zephyr\boards\espressif\esp32s3_devkitc\esp32s3_devkitc-pinctrl.dtsi:29 */
				bias-pull-up;          /* in zephyr\boards\espressif\esp32s3_devkitc\esp32s3_devkitc-pinctrl.dtsi:30 */
			};
		};

		/* node '/pin-controller/i2c0_default' defined in zephyr\boards\espressif\esp32s3_devkitc\esp32s3_devkitc-pinctrl.dtsi:34 */
		i2c0_default: i2c0_default {
			phandle = < 0x7 >; /* in zephyr\boards\espressif\esp32s3_devkitc\esp32s3_devkitc_procpu.dts:78 */

			/* node '/pin-controller/i2c0_default/group1' defined in zephyr\boards\espressif\esp32s3_devkitc\esp32s3_devkitc-pinctrl.dtsi:35 */
			group1 {
				pinmux = < 0x2d1681 >,
				         < 0x2c9642 >; /* in zephyr\boards\espressif\esp32s3_devkitc\esp32s3_devkitc-pinctrl.dtsi:36 */
				bias-pull-up;          /* in zephyr\boards\espressif\esp32s3_devkitc\esp32s3_devkitc-pinctrl.dtsi:38 */
				drive-open-drain;      /* in zephyr\boards\espressif\esp32s3_devkitc\esp32s3_devkitc-pinctrl.dtsi:39 */
				output-high;           /* in zephyr\boards\espressif\esp32s3_devkitc\esp32s3_devkitc-pinctrl.dtsi:40 */
			};
		};

		/* node '/pin-controller/i2c1_default' defined in zephyr\boards\espressif\esp32s3_devkitc\esp32s3_devkitc-pinctrl.dtsi:44 */
		i2c1_default: i2c1_default {
			phandle = < 0x8 >; /* in zephyr\boards\espressif\esp32s3_devkitc\esp32s3_devkitc_procpu.dts:84 */

			/* node '/pin-controller/i2c1_default/group1' defined in zephyr\boards\espressif\esp32s3_devkitc\esp32s3_devkitc-pinctrl.dtsi:45 */
			group1 {
				pinmux = < 0x2e1704 >,
				         < 0x2d96c5 >; /* in zephyr\boards\espressif\esp32s3_devkitc\esp32s3_devkitc-pinctrl.dtsi:46 */
				bias-pull-up;          /* in zephyr\boards\espressif\esp32s3_devkitc\esp32s3_devkitc-pinctrl.dtsi:48 */
				drive-open-drain;      /* in zephyr\boards\espressif\esp32s3_devkitc\esp32s3_devkitc-pinctrl.dtsi:49 */
				output-high;           /* in zephyr\boards\espressif\esp32s3_devkitc\esp32s3_devkitc-pinctrl.dtsi:50 */
			};
		};

		/* node '/pin-controller/i2s0_default' defined in zephyr\boards\espressif\esp32s3_devkitc\esp32s3_devkitc-pinctrl.dtsi:54 */
		i2s0_default: i2s0_default {
			phandle = < 0xa >; /* in zephyr\boards\espressif\esp32s3_devkitc\esp32s3_devkitc_procpu.dts:89 */

			/* node '/pin-controller/i2s0_default/group1' defined in zephyr\boards\espressif\esp32s3_devkitc\esp32s3_devkitc-pinctrl.dtsi:55 */
			group1 {
				pinmux = < 0xbffea >,
				         < 0xc0624 >,
				         < 0xb05a5 >,
				         < 0xcffe6 >,
				         < 0xff8669 >; /* in zephyr\boards\espressif\esp32s3_devkitc\esp32s3_devkitc-pinctrl.dtsi:56 */
			};
		};

		/* node '/pin-controller/i2s1_default' defined in zephyr\boards\espressif\esp32s3_devkitc\esp32s3_devkitc-pinctrl.dtsi:64 */
		i2s1_default: i2s1_default {
			phandle = < 0xb >; /* in zephyr\boards\espressif\esp32s3_devkitc\esp32s3_devkitc_procpu.dts:94 */

			/* node '/pin-controller/i2s1_default/group1' defined in zephyr\boards\espressif\esp32s3_devkitc\esp32s3_devkitc-pinctrl.dtsi:65 */
			group1 {
				pinmux = < 0xafff0 >,
				         < 0xe8744 >,
				         < 0xe0705 >,
				         < 0xf7fc6 >,
				         < 0xff878c >; /* in zephyr\boards\espressif\esp32s3_devkitc\esp32s3_devkitc-pinctrl.dtsi:66 */
			};
		};

		/* node '/pin-controller/spim2_default' defined in zephyr\boards\espressif\esp32s3_devkitc\esp32s3_devkitc-pinctrl.dtsi:74 */
		spim2_default: spim2_default {
			phandle = < 0xc >; /* in zephyr\boards\espressif\esp32s3_devkitc\esp32s3_devkitc_procpu.dts:102 */

			/* node '/pin-controller/spim2_default/group1' defined in zephyr\boards\espressif\esp32s3_devkitc\esp32s3_devkitc-pinctrl.dtsi:75 */
			group1 {
				pinmux = < 0xff998d >,
				         < 0x32ffcc >,
				         < 0x377fca >; /* in zephyr\boards\espressif\esp32s3_devkitc\esp32s3_devkitc-pinctrl.dtsi:76 */
			};

			/* node '/pin-controller/spim2_default/group2' defined in zephyr\boards\espressif\esp32s3_devkitc\esp32s3_devkitc-pinctrl.dtsi:81 */
			group2 {
				pinmux = < 0x33ffcb >; /* in zephyr\boards\espressif\esp32s3_devkitc\esp32s3_devkitc-pinctrl.dtsi:82 */
				output-low;            /* in zephyr\boards\espressif\esp32s3_devkitc\esp32s3_devkitc-pinctrl.dtsi:83 */
			};
		};

		/* node '/pin-controller/spim3_default' defined in zephyr\boards\espressif\esp32s3_devkitc\esp32s3_devkitc-pinctrl.dtsi:87 */
		spim3_default: spim3_default {
			phandle = < 0xd >; /* in zephyr\boards\espressif\esp32s3_devkitc\esp32s3_devkitc_procpu.dts:110 */

			/* node '/pin-controller/spim3_default/group1' defined in zephyr\boards\espressif\esp32s3_devkitc\esp32s3_devkitc-pinctrl.dtsi:88 */
			group1 {
				pinmux = < 0xff90e5 >,
				         < 0x217fe4 >,
				         < 0x23ffe6 >; /* in zephyr\boards\espressif\esp32s3_devkitc\esp32s3_devkitc-pinctrl.dtsi:89 */
			};

			/* node '/pin-controller/spim3_default/group2' defined in zephyr\boards\espressif\esp32s3_devkitc\esp32s3_devkitc-pinctrl.dtsi:94 */
			group2 {
				pinmux = < 0x227fe7 >; /* in zephyr\boards\espressif\esp32s3_devkitc\esp32s3_devkitc-pinctrl.dtsi:95 */
				output-low;            /* in zephyr\boards\espressif\esp32s3_devkitc\esp32s3_devkitc-pinctrl.dtsi:96 */
			};
		};

		/* node '/pin-controller/twai_default' defined in zephyr\boards\espressif\esp32s3_devkitc\esp32s3_devkitc-pinctrl.dtsi:100 */
		twai_default: twai_default {
			phandle = < 0xe >; /* in zephyr\boards\espressif\esp32s3_devkitc\esp32s3_devkitc_procpu.dts:115 */

			/* node '/pin-controller/twai_default/group1' defined in zephyr\boards\espressif\esp32s3_devkitc\esp32s3_devkitc-pinctrl.dtsi:101 */
			group1 {
				pinmux = < 0x3a7fc5 >,
				         < 0xff9d06 >; /* in zephyr\boards\espressif\esp32s3_devkitc\esp32s3_devkitc-pinctrl.dtsi:102 */
			};
		};
	};

	/* node '/clock' defined in zephyr\dts\xtensa\espressif\esp32s3\esp32s3_common.dtsi:88 */
	clock: clock {
		compatible = "espressif,esp32-clock"; /* in zephyr\dts\xtensa\espressif\esp32s3\esp32s3_common.dtsi:89 */
		fast-clk-src = < 0x1 >;               /* in zephyr\dts\xtensa\espressif\esp32s3\esp32s3_common.dtsi:90 */
		slow-clk-src = < 0x0 >;               /* in zephyr\dts\xtensa\espressif\esp32s3\esp32s3_common.dtsi:91 */
		#clock-cells = < 0x1 >;               /* in zephyr\dts\xtensa\espressif\esp32s3\esp32s3_common.dtsi:92 */
		status = "okay";                      /* in zephyr\dts\xtensa\espressif\esp32s3\esp32s3_common.dtsi:93 */
		phandle = < 0x3 >;                    /* in zephyr\dts\xtensa\espressif\esp32s3\esp32s3_common.dtsi:194 */
	};

	/* node '/buttons' defined in zephyr\boards\espressif\esp32s3_devkitc\esp32s3_devkitc_procpu.dts:34 */
	buttons {
		compatible = "gpio-keys"; /* in zephyr\boards\espressif\esp32s3_devkitc\esp32s3_devkitc_procpu.dts:35 */

		/* node '/buttons/button_0' defined in zephyr\boards\espressif\esp32s3_devkitc\esp32s3_devkitc_procpu.dts:37 */
		button0: button_0 {
			gpios = < &gpio0 0x0 0x11 >; /* in zephyr\boards\espressif\esp32s3_devkitc\esp32s3_devkitc_procpu.dts:38 */
			label = "BOOT Button";       /* in zephyr\boards\espressif\esp32s3_devkitc\esp32s3_devkitc_procpu.dts:39 */
			zephyr,code = < 0xb >;       /* in zephyr\boards\espressif\esp32s3_devkitc\esp32s3_devkitc_procpu.dts:40 */
		};
	};

	/* node '/leds' defined in ..\ZephyrWrokSpace\lomico\zephyr-course\my_work_space\hello_led\boards\esp32s3_devkitc_procpu.overlay:12 */
	leds {
		compatible = "gpio-leds"; /* in ..\ZephyrWrokSpace\lomico\zephyr-course\my_work_space\hello_led\boards\esp32s3_devkitc_procpu.overlay:13 */

		/* node '/leds/led_0' defined in ..\ZephyrWrokSpace\lomico\zephyr-course\my_work_space\hello_led\boards\esp32s3_devkitc_procpu.overlay:14 */
		myled: led_0 {
			gpios = < &gpio0 0x26 0x0 >; /* in ..\ZephyrWrokSpace\lomico\zephyr-course\my_work_space\hello_led\boards\esp32s3_devkitc_procpu.overlay:15 */
		};
	};
};
